VERSION ""

NS_ :

BS_:

BU_: VoltTemp_7 VoltTemp_6 VoltTemp_5 VoltTemp_4 VoltTemp_3 VoltTemp_2 VoltTemp_1 VoltTemp_0 BPS Amperes TPEE_MPPT_C TPEE_MPPT_B TPEE_MPPT_A Telemetry Pump Pedals PDU LV_Carrier External Dashboard_Display ChargerInterface Controls VCU Elcon Lighting_Rear Lighting_Right Lighting_Left Lighting_Front Lighting_Canopy Prohelion_WaveSculptor22 Bosch_LWS Vector__XXX

VAL_TABLE_ BPS_Amperes_Fault 0 "OK" 1 "Out-of-Bounds" 2 "Over-Current (Discharge)" 3 "Over-Current (Charge)" 4 "Message Watchdog" ;
VAL_TABLE_ BPS_Volt_Tap_Fault 0 "OK" 1 "BQ I2C Read Error" 2 "Out-of-Bounds" 3 "Over-Voltage" 4 "Under-Voltage" 5 "Message Watchdog" ;
VAL_TABLE_ BPS_Temp_Tap_Fault 0 "OK" 1 "Out-of-Bounds (Short to GND)" 2 "Out-of-Bounds (Short to VCC)" 3 "Disconnected" 4 "Over-Temperature" 5 "Charge Over-Temperature" 6 "Under-Temperature" 7 "Charge Under-Temperature" 8 "Message Watchdog" ;
VAL_TABLE_ BPS_Module_Override 0 "NORMAL_OPERATION" 1 "VOLTAGE_OVERRIDE" 2 "TEMP_OVERRIDE" 3 "OVERRIDE_ALL" ;
VAL_TABLE_ BQ25756E_Error 0 "OK" 1 "i2c_error" 2 "Input_UV" 3 "Input_OV" 4 "Battery_OC" 5 "Battery_OV" 6 "Over-Temperature" ;
VAL_TABLE_ Motor_Command_Source 0 "VCU" 1 "Tritium External" ;
VAL_TABLE_ Supplemental_Battery_Fault 0 "OK" 1 "Under-Voltage" 2 "Over-Voltage" 3 "Over-Current (Discharge)" 4 "Over-Current (Charge)" 5 "Unknown Fault" ;
VAL_TABLE_ VCU_FSM_State 0 "INIT" 1 "FORWARD_DRIVE" 2 "NEUTRAL_DRIVE" 3 "REVERSE_DRIVE" 4 "REGEN" 5 "CRUISE_CONTROL" 6 "DISABLED" 7 "VEHICLE_NOT_READY" ;
VAL_TABLE_ Generic_TrueFalse 0 "False" 1 "True" ;
VAL_TABLE_ Fusebox_Assignments 0 "VCU" 1 "Dashboard" 2 "Horn" 3 "Lights" 4 "Pi + Display" 5 "Pedals" 6 "Cameras" 7 "Unassigned_0" 8 "Battery" 9 "MPPTs" 10 "Motor Controller" 11 "Telemetry + Data Acq" 12 "Pump" 13 "Unassigned_1" 14 "Unassigned_2" 15 "PDE Fans" ;
VAL_TABLE_ Generic_Active 0 "Inactive" 1 "Active" ;
VAL_TABLE_ SuppCharger_Status 0 "Charge Disabled" 1 "Trickle Charging" 2 "Precharge" 3 "Fast Charging" 4 "Taper" 5 "ERROR" 6 "Topping Off" 7 "Done" ;
VAL_TABLE_ ContactorState 0 "Open" 1 "Closed" ;
VAL_TABLE_ Lighting_Board_Fault 0 "OK" 1 "Addr LED Undercurrent" 2 "LED0 Undercurrent" 3 "LED1 Undercurrent" 4 "Addr LED Overcurrent" 5 "LED0 Overcurrent" 6 "LED1 Overcurrent" 7 "Light Command Watchdog" 8 "Watchdog" ;
VAL_TABLE_ MPPT_ControlMode 0 "Disabled" 1 "Enabled" 2 "Enabled - Constant Voltage" ;
VAL_TABLE_ Generic_OnOff 0 "Off" 1 "On" ;
VAL_TABLE_ Button_Pressed 0 "-" 1 "Pressed" ;
VAL_TABLE_ Switch_Selected 0 "-" 1 "Selected" ;
VAL_TABLE_ Generic_Enable 0 "Disabled" 1 "Enabled" ;
VAL_TABLE_ Generic_OK 0 "NOT OK" 1 "OK" ;
VAL_TABLE_ Generic_Fault 0 "OK" 1 "FAULT" ;
VAL_TABLE_ MPPT_Fault 0 "OK" 1 "Configuration Error" 2 "Input Over Voltage" 3 "Output Over Voltage" 4 "Output Over Current" 5 "Input Over Current" 6 "Input Under Current" 7 "Phase Over Current" 8 "Unknown Fault" ;
VAL_TABLE_ MPPT_Mode 0 "Constant Input Voltage" 1 "Constant Input Current" 2 "Minimum Input Current" 3 "Constant Output Voltage" 4 "Constant Output Current" 5 "Temperature De-Rating" 6 "FAULT" ;
VAL_TABLE_ BPS_Fault 0 "OK" 1 "Overvoltage" 2 "Undervoltage" 3 "Regen" 4 "Overtemperature" 5 "Elcon" 6 "Array Precharge Timeout" 7 "Internal Watchdog" 8 "Segment Watchdog" 9 "HV Plus Contactor Sense" 10 "HV Minus Contactor Sense" 11 "Array Contactor Sense" 12 "Array Pchg Contactor Sense" 13 "Estop 1" 14 "Estop 2" 15 "Estop 3" 16 "Charging Overcurrent" 17 "Discharging Overcurrent" 18 "Amperes Watchdog" ;
VAL_TABLE_ Controls_Leader_Fault 0 "OK" 1 "Bosch LWS Watchdog" 2 "BPS Watchdog" 3 "Invalid Driver Inputs" 4 "Lighting Board Fault" 5 "Lighting Board Watchdog" ;
VAL_TABLE_ HSS_SetState 0 "Do Nothing" 1 "Toggle On" 2 "Toggle Off" ;
VAL_TABLE_ Elcon_MuxPage 1 "Page 1" 2 "Page 2" 3 "Page 3" 4 "Page 4" 5 "Page 5" ;
VAL_TABLE_ Lighting_CustomModes 0 "Off" 1 "Mode 1 Active" 2 "Mode 2 Active" 3 "Mode 3 Active" ;
VAL_TABLE_ Generic_Limit 0 "OK" 1 "LIMIT" ;
VAL_TABLE_ LWS_Config 3 "Sets the signal LWS_Angle to 0°" 5 "Resets calibration status" ;
VAL_TABLE_ LWS_TrimmingStatus 0 "FAULT - Sensor Not Trimmed" 1 "Sensor Trimmed" ;
VAL_TABLE_ LWS_Fault 0 "OK" 1 "Internal Fault" ;
VAL_TABLE_ LWS_CalibrationStatus 0 "Sensor Not Calibrated" 1 "Sensor Calibrated" ;

BO_ 2 BPS_VT0_Voltage_Arr: 4 VoltTemp_0
 SG_ BPS_Tap_idx : 0|5@1+ (1,0) [0|31] "" Vector__XXX
 SG_ BPS_Voltage_Tap_Data : 8|16@1+ (0.001,0) [0|65.535] "V" Vector__XXX
 SG_ BPS_Voltage_Tap_Fault : 24|8@1+ (1,0) [0|0] "" Vector__XXX

BO_ 3 BPS_VT1_Voltage_Arr: 4 VoltTemp_1
 SG_ BPS_Tap_idx : 0|5@1+ (1,0) [0|31] "" Vector__XXX
 SG_ BPS_Voltage_Tap_Data : 8|16@1+ (0.001,0) [0|65.535] "V" Vector__XXX
 SG_ BPS_Voltage_Tap_Fault : 24|8@1+ (1,0) [0|0] "" Vector__XXX

BO_ 4 BPS_VT2_Voltage_Arr: 4 VoltTemp_2
 SG_ BPS_Tap_idx : 0|5@1+ (1,0) [0|31] "" Vector__XXX
 SG_ BPS_Voltage_Tap_Data : 8|16@1+ (0.001,0) [0|65.535] "V" Vector__XXX
 SG_ BPS_Voltage_Tap_Fault : 24|8@1+ (1,0) [0|0] "" Vector__XXX

BO_ 5 BPS_VT3_Voltage_Arr: 4 VoltTemp_3
 SG_ BPS_Tap_idx : 0|5@1+ (1,0) [0|31] "" Vector__XXX
 SG_ BPS_Voltage_Tap_Data : 8|16@1+ (0.001,0) [0|65.535] "V" Vector__XXX
 SG_ BPS_Voltage_Tap_Fault : 24|8@1+ (1,0) [0|0] "" Vector__XXX

BO_ 6 BPS_VT4_Voltage_Arr: 4 VoltTemp_4
 SG_ BPS_Tap_idx : 0|5@1+ (1,0) [0|31] "" Vector__XXX
 SG_ BPS_Voltage_Tap_Data : 8|16@1+ (0.001,0) [0|65.535] "V" Vector__XXX
 SG_ BPS_Voltage_Tap_Fault : 24|8@1+ (1,0) [0|0] "" Vector__XXX

BO_ 7 BPS_VT5_Voltage_Arr: 4 VoltTemp_5
 SG_ BPS_Tap_idx : 0|5@1+ (1,0) [0|31] "" Vector__XXX
 SG_ BPS_Voltage_Tap_Data : 8|16@1+ (0.001,0) [0|65.535] "V" Vector__XXX
 SG_ BPS_Voltage_Tap_Fault : 24|8@1+ (1,0) [0|0] "" Vector__XXX

BO_ 8 BPS_VT6_Voltage_Arr: 4 VoltTemp_6
 SG_ BPS_Tap_idx : 0|5@1+ (1,0) [0|31] "" Vector__XXX
 SG_ BPS_Voltage_Tap_Data : 8|16@1+ (0.001,0) [0|65.535] "V" Vector__XXX
 SG_ BPS_Voltage_Tap_Fault : 24|8@1+ (1,0) [0|0] "" Vector__XXX

BO_ 9 BPS_VT7_Voltage_Arr: 4 VoltTemp_7
 SG_ BPS_Tap_idx : 0|5@1+ (1,0) [0|31] "" Vector__XXX
 SG_ BPS_Voltage_Tap_Data : 8|16@1+ (0.001,0) [0|65.535] "V" Vector__XXX
 SG_ BPS_Voltage_Tap_Fault : 24|8@1+ (1,0) [0|0] "" Vector__XXX

BO_ 10 BPS_Pack_Current: 5 Amperes
 SG_ BPS_Amperes_Fault : 0|8@1+ (1,0) [0|255] "" Vector__XXX
 SG_ Main_Battery_Current : 8|24@1- (0.001,0) [-8388.608|8388.607] "A" Vector__XXX
 SG_ FrameID_Amperes : 32|8@1+ (1,0) [0|255] "" Vector__XXX

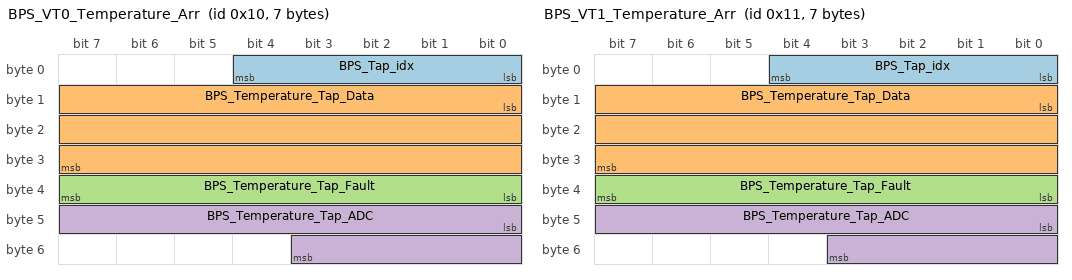
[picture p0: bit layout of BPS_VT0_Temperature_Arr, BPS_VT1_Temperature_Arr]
BO_ 16 BPS_VT0_Temperature_Arr: 7 VoltTemp_0
 SG_ BPS_Tap_idx : 0|5@1+ (1,0) [0|31] "" Vector__XXX
 SG_ BPS_Temperature_Tap_Data : 8|24@1- (0.001,0) [-8388.608|8388.607] "°C" Vector__XXX
 SG_ BPS_Temperature_Tap_Fault : 32|8@1+ (1,0) [0|255] "" Vector__XXX
 SG_ BPS_Temperature_Tap_ADC : 40|12@1+ (1,0) [0|4095] "" Vector__XXX

BO_ 17 BPS_VT1_Temperature_Arr: 7 VoltTemp_1
 SG_ BPS_Tap_idx : 0|5@1+ (1,0) [0|31] "" Vector__XXX
 SG_ BPS_Temperature_Tap_Data : 8|24@1- (0.001,0) [-8388.608|8388.607] "°C" Vector__XXX
 SG_ BPS_Temperature_Tap_Fault : 32|8@1+ (1,0) [0|255] "" Vector__XXX
 SG_ BPS_Temperature_Tap_ADC : 40|12@1+ (1,0) [0|4095] "" Vector__XXX

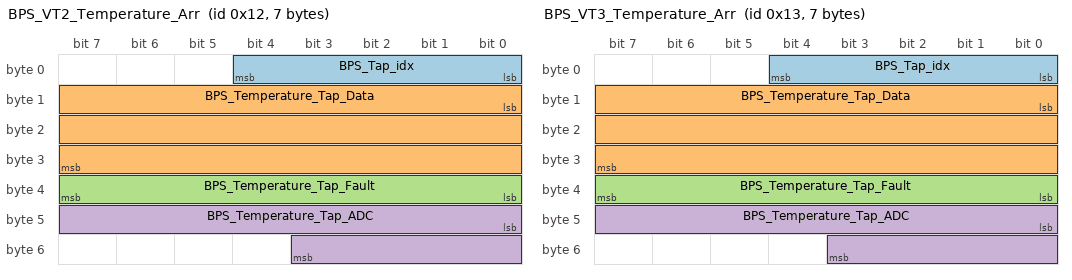
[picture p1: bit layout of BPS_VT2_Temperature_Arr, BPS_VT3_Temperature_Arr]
BO_ 18 BPS_VT2_Temperature_Arr: 7 VoltTemp_2
 SG_ BPS_Tap_idx : 0|5@1+ (1,0) [0|31] "" Vector__XXX
 SG_ BPS_Temperature_Tap_Data : 8|24@1- (0.001,0) [-8388.608|8388.607] "°C" Vector__XXX
 SG_ BPS_Temperature_Tap_Fault : 32|8@1+ (1,0) [0|255] "" Vector__XXX
 SG_ BPS_Temperature_Tap_ADC : 40|12@1+ (1,0) [0|4095] "" Vector__XXX

BO_ 19 BPS_VT3_Temperature_Arr: 7 VoltTemp_3
 SG_ BPS_Tap_idx : 0|5@1+ (1,0) [0|31] "" Vector__XXX
 SG_ BPS_Temperature_Tap_Data : 8|24@1- (0.001,0) [-8388.608|8388.607] "°C" Vector__XXX
 SG_ BPS_Temperature_Tap_Fault : 32|8@1+ (1,0) [0|255] "" Vector__XXX
 SG_ BPS_Temperature_Tap_ADC : 40|12@1+ (1,0) [0|4095] "" Vector__XXX

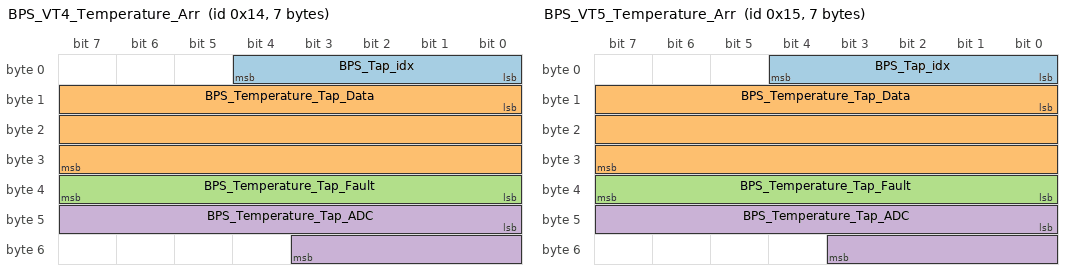
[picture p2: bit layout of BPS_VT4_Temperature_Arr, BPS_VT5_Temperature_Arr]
BO_ 20 BPS_VT4_Temperature_Arr: 7 VoltTemp_4
 SG_ BPS_Tap_idx : 0|5@1+ (1,0) [0|31] "" Vector__XXX
 SG_ BPS_Temperature_Tap_Data : 8|24@1- (0.001,0) [-8388.608|8388.607] "°C" Vector__XXX
 SG_ BPS_Temperature_Tap_Fault : 32|8@1+ (1,0) [0|255] "" Vector__XXX
 SG_ BPS_Temperature_Tap_ADC : 40|12@1+ (1,0) [0|4095] "" Vector__XXX

BO_ 21 BPS_VT5_Temperature_Arr: 7 VoltTemp_5
 SG_ BPS_Tap_idx : 0|5@1+ (1,0) [0|31] "" Vector__XXX
 SG_ BPS_Temperature_Tap_Data : 8|24@1- (0.001,0) [-8388.608|8388.607] "°C" Vector__XXX
 SG_ BPS_Temperature_Tap_Fault : 32|8@1+ (1,0) [0|255] "" Vector__XXX
 SG_ BPS_Temperature_Tap_ADC : 40|12@1+ (1,0) [0|4095] "" Vector__XXX

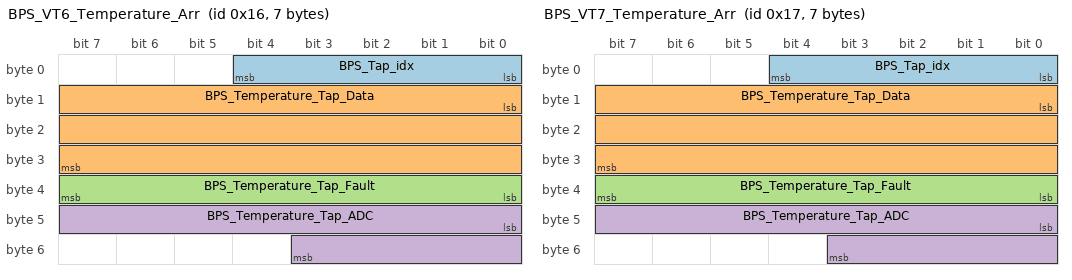
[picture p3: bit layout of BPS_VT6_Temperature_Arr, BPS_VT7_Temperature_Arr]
BO_ 22 BPS_VT6_Temperature_Arr: 7 VoltTemp_6
 SG_ BPS_Tap_idx : 0|5@1+ (1,0) [0|31] "" Vector__XXX
 SG_ BPS_Temperature_Tap_Data : 8|24@1- (0.001,0) [-8388.608|8388.607] "°C" Vector__XXX
 SG_ BPS_Temperature_Tap_Fault : 32|8@1+ (1,0) [0|255] "" Vector__XXX
 SG_ BPS_Temperature_Tap_ADC : 40|12@1+ (1,0) [0|4095] "" Vector__XXX

BO_ 23 BPS_VT7_Temperature_Arr: 7 VoltTemp_7
 SG_ BPS_Tap_idx : 0|5@1+ (1,0) [0|31] "" Vector__XXX
 SG_ BPS_Temperature_Tap_Data : 8|24@1- (0.001,0) [-8388.608|8388.607] "°C" Vector__XXX
 SG_ BPS_Temperature_Tap_Fault : 32|8@1+ (1,0) [0|255] "" Vector__XXX
 SG_ BPS_Temperature_Tap_ADC : 40|12@1+ (1,0) [0|4095] "" Vector__XXX

BO_ 1877 BPS_Pack_Current_ADC: 3 Amperes
 SG_ Main_Battery_Current_ADC : 0|12@1+ (1,0) [0|4095] "" Vector__XXX
 SG_ FrameID_Amperes : 16|8@1+ (1,0) [0|255] "" Vector__XXX

BO_ 1952 BPS_Balance_Discharge: 1 BPS
 SG_ BPS_Segment_idx : 0|3@1+ (1,0) [0|7] "" Vector__XXX
 SG_ BPS_Tap_idx : 3|5@1+ (1,0) [0|31] "" Vector__XXX

BO_ 1 BPS_Status: 8 BPS
 SG_ BPS_Fault : 0|8@1+ (1,0) [0|0] "" Vector__XXX
 SG_ BPS_Charge_OK : 8|1@1+ (1,0) [0|0] "" Vector__XXX
 SG_ BPS_Regen_OK : 9|1@1+ (1,0) [0|0] "" Vector__XXX
 SG_ HV_Plus_Contactor_State : 10|1@1+ (1,0) [0|0] "" Vector__XXX
 SG_ HV_Minus_Contactor_State : 11|1@1+ (1,0) [0|0] "" Vector__XXX
 SG_ Array_Contactor_State : 12|1@1+ (1,0) [0|0] "" Vector__XXX
 SG_ Array_Precharge_Contactor_State : 13|1@1+ (1,0) [0|0] "" Vector__XXX
 SG_ Main_Battery_Voltage : 16|24@1+ (0.001,0) [0|16777.215] "V" Vector__XXX
 SG_ Main_Battery_Avg_Temperature : 40|16@1- (0.01,0) [-327.68|327.67] "°C" Vector__XXX
 SG_ BPS_Segment0_Status : 56|1@1+ (1,0) [0|0] "" Vector__XXX
 SG_ BPS_Segment1_Status : 57|1@1+ (1,0) [0|0] "" Vector__XXX
 SG_ BPS_Segment2_Status : 58|1@1+ (1,0) [0|0] "" Vector__XXX
 SG_ BPS_Segment3_Status : 59|1@1+ (1,0) [0|0] "" Vector__XXX
 SG_ BPS_Segment4_Status : 60|1@1+ (1,0) [0|0] "" Vector__XXX
 SG_ BPS_Segment5_Status : 61|1@1+ (1,0) [0|0] "" Vector__XXX
 SG_ BPS_Segment6_Status : 62|1@1+ (1,0) [0|0] "" Vector__XXX
 SG_ BPS_Segment7_Status : 63|1@1+ (1,0) [0|0] "" Vector__XXX

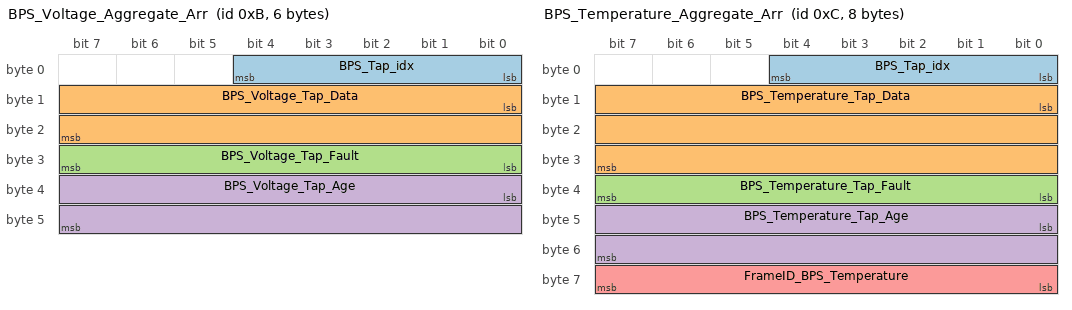
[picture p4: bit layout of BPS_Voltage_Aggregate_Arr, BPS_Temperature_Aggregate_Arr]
BO_ 11 BPS_Voltage_Aggregate_Arr: 6 BPS
 SG_ BPS_Tap_idx : 0|5@1+ (1,0) [0|31] "" Vector__XXX
 SG_ BPS_Voltage_Tap_Data : 8|16@1+ (0.001,0) [0|65.535] "V" Vector__XXX
 SG_ BPS_Voltage_Tap_Fault : 24|8@1+ (1,0) [0|0] "" Vector__XXX
 SG_ BPS_Voltage_Tap_Age : 32|16@1+ (1,0) [0|65535] "ms" Vector__XXX

BO_ 12 BPS_Temperature_Aggregate_Arr: 8 BPS
 SG_ BPS_Tap_idx : 0|5@1+ (1,0) [0|31] "" Vector__XXX
 SG_ BPS_Temperature_Tap_Data : 8|24@1- (0.001,0) [-8388.608|8388.607] "°C" Vector__XXX
 SG_ BPS_Temperature_Tap_Fault : 32|8@1+ (1,0) [0|255] "" Vector__XXX
 SG_ BPS_Temperature_Tap_Age : 40|16@1+ (1,0) [0|65535] "ms" Vector__XXX
 SG_ FrameID_BPS_Temperature : 56|8@1+ (1,0) [0|255] "" Vector__XXX

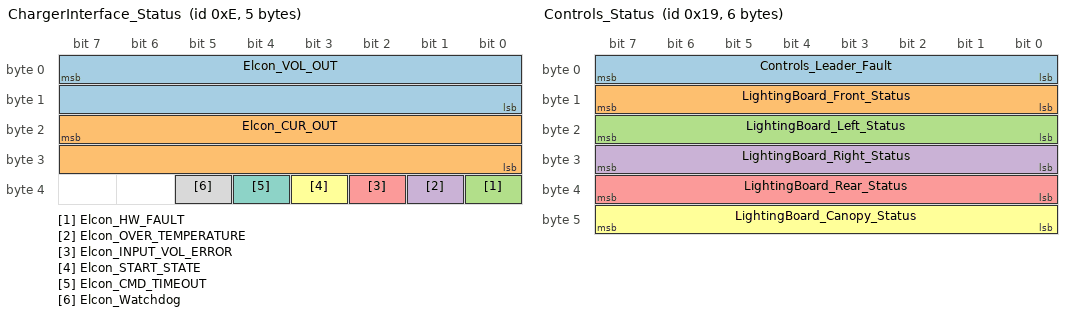
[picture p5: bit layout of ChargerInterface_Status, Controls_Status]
BO_ 14 ChargerInterface_Status: 5 ChargerInterface
 SG_ Elcon_VOL_OUT : 7|16@0+ (0.1,0) [0|6553.5] "V" Vector__XXX
 SG_ Elcon_CUR_OUT : 23|16@0+ (0.1,0) [0|6553.5] "A" Vector__XXX
 SG_ Elcon_HW_FAULT : 32|1@0+ (1,0) [0|1] "" Vector__XXX
 SG_ Elcon_OVER_TEMPERATURE : 33|1@0+ (1,0) [0|1] "" Vector__XXX
 SG_ Elcon_INPUT_VOL_ERROR : 34|1@0+ (1,0) [0|1] "" Vector__XXX
 SG_ Elcon_START_STATE : 35|1@0+ (1,0) [0|1] "" Vector__XXX
 SG_ Elcon_CMD_TIMEOUT : 36|1@0+ (1,0) [0|1] "" Vector__XXX
 SG_ Elcon_Watchdog : 37|1@0+ (1,0) [0|1] "" Vector__XXX

BO_ 15 BPS_Fault_Val_Arr: 6 BPS
 SG_ BPS_Tap_idx : 0|5@1+ (1,0) [0|31] "" Vector__XXX
 SG_ BPS_Voltage_Tap_Data : 8|16@1+ (0.001,0) [0|65.535] "V" Vector__XXX
 SG_ BPS_Temperature_Tap_Data : 24|24@1- (0.001,0) [-8388.608|8388.607] "°C" Vector__XXX

BO_ 24 VCU_Status: 6 VCU
 SG_ VCU_FSM_State : 0|4@1+ (1,0) [0|15] "" Vector__XXX
 SG_ Motor_Ready : 4|1@1+ (1,0) [0|0] "" Vector__XXX
 SG_ Motor_Precharge_Contactor_State : 5|1@1+ (1,0) [0|0] "" Vector__XXX
 SG_ Motor_Contactor_State : 6|1@1+ (1,0) [0|0] "" Vector__XXX
 SG_ VCU_Driver_Input_Watchdog : 7|1@1+ (1,0) [0|0] "" Vector__XXX
 SG_ VCU_Pedals_Watchdog : 8|1@1+ (1,0) [0|0] "" Vector__XXX
 SG_ VCU_BPS_Watchdog : 9|1@1+ (1,0) [0|0] "" Vector__XXX
 SG_ VCU_Steering_Angle_Watchdog : 10|1@1+ (1,0) [0|1] "" Vector__XXX
 SG_ VCU_BPS_FAULT_DETECTED : 11|1@1+ (1,0) [0|1] "" Vector__XXX
 SG_ VCU_CONTROLS_FAULT_DETECTED : 12|1@1+ (1,0) [0|1] "" Vector__XXX
 SG_ VCU_MTR_FAULT_DETECTED : 13|1@1+ (1,0) [0|1] "" Vector__XXX
 SG_ VCU_PEDALS_FAULT_DETECTED : 14|1@1+ (1,0) [0|1] "" Vector__XXX
 SG_ VCU_STEERING_FAULT_DETECTED : 15|1@1+ (1,0) [0|1] "" Vector__XXX
 SG_ VCU_MotorCommandSource : 16|1@1+ (1,0) [0|1] "" Vector__XXX
 SG_ VCU_Regen_Active : 17|1@1+ (1,0) [0|0] "" Vector__XXX
 SG_ VCU_Regen_OK : 18|1@1+ (1,0) [0|0] "" Vector__XXX
 SG_ VCU_MTR_PCHG_TIMEOUT : 19|1@1+ (1,0) [0|1] "" Vector__XXX
 SG_ VCU_MTR_PCHG_CONT_TIMEOUT : 20|1@1+ (1,0) [0|1] "" Vector__XXX
 SG_ VCU_MTR_PCHG_CONT_MISMATCH : 21|1@1+ (1,0) [0|1] "" Vector__XXX
 SG_ VCU_MTR_CONT_MISMATCH : 22|1@1+ (1,0) [0|1] "" Vector__XXX
 SG_ VCU_MTR_CONT_TIMEOUT : 23|1@1+ (1,0) [0|1] "" Vector__XXX
 SG_ VCU_PCHG_OV : 24|1@1+ (1,0) [0|1] "" Vector__XXX
 SG_ VCU_PCHG_UV : 25|1@1+ (1,0) [0|1] "" Vector__XXX
 SG_ VCU_MTR_OV : 26|1@1+ (1,0) [0|1] "" Vector__XXX
 SG_ VCU_MTR_UV : 27|1@1+ (1,0) [0|1] "" Vector__XXX
 SG_ VCU_OTHER_FAULT : 28|1@1+ (1,0) [0|1] "" Vector__XXX
 SG_ VCU_MTR_DIR_CHANGE_LOCKOUT : 29|1@1+ (1,0) [0|1] "" Vector__XXX
 SG_ VCU_TIPPING_WARNING : 30|1@1+ (1,0) [0|1] "" Vector__XXX
 SG_ VCU_WARN_REGEN_NOT_ALLOW : 31|1@1+ (1,0) [0|1] "" Vector__XXX
 SG_ VCU_WARN_REGEN_NOT_EN : 32|1@1+ (1,0) [0|1] "" Vector__XXX
 SG_ VCU_FSM_INP_BRAKE : 33|1@1+ (1,0) [0|1] "" Vector__XXX
 SG_ VCU_FSM_INP_PCHG_OK : 34|1@1+ (1,0) [0|1] "" Vector__XXX
 SG_ VCU_FSM_INP_CRUISE_REQ : 35|1@1+ (1,0) [0|1] "" Vector__XXX
 SG_ VCU_FSM_INP_REGEN_REQ : 36|1@1+ (1,0) [0|1] "" Vector__XXX
 SG_ VCU_FSM_INP_REGEN_ENABLE : 37|1@1+ (1,0) [0|1] "" Vector__XXX
 SG_ VCU_FSM_INP_REGEN_RDY : 38|1@1+ (1,0) [0|1] "" Vector__XXX
 SG_ VCU_FSM_INP_FORWARD : 39|1@1+ (1,0) [0|1] "" Vector__XXX
 SG_ VCU_FSM_INP_NEUTRAL : 40|1@1+ (1,0) [0|1] "" Vector__XXX
 SG_ VCU_FSM_INP_REVERSE : 41|1@1+ (1,0) [0|1] "" Vector__XXX

BO_ 25 Controls_Status: 6 Controls
 SG_ Controls_Leader_Fault : 0|8@1+ (1,0) [0|0] "" Vector__XXX
 SG_ LightingBoard_Front_Status : 8|8@1+ (1,0) [0|0] "" Vector__XXX
 SG_ LightingBoard_Left_Status : 16|8@1+ (1,0) [0|0] "" Vector__XXX
 SG_ LightingBoard_Right_Status : 24|8@1+ (1,0) [0|0] "" Vector__XXX
 SG_ LightingBoard_Rear_Status : 32|8@1+ (1,0) [0|0] "" Vector__XXX
 SG_ LightingBoard_Canopy_Status : 40|8@1+ (1,0) [0|0] "" Vector__XXX

BO_ 32 BPS_Precharge_Voltages: 6 BPS
 SG_ BPS_Precharge_Battery_Voltage : 0|24@1+ (0.001,0) [0|16777.215] "V" Vector__XXX
 SG_ BPS_Precharge_Array_Voltage : 24|24@1+ (0.001,0) [0|16777.215] "V" Vector__XXX

BO_ 33 VCU_Precharge_Voltages: 6 VCU
 SG_ VCU_Precharge_Battery_Voltage : 0|24@1+ (0.001,0) [0|16777.215] "V" Vector__XXX
 SG_ VCU_Precharge_Motor_Voltage : 24|24@1+ (0.001,0) [0|16777.215] "V" Vector__XXX

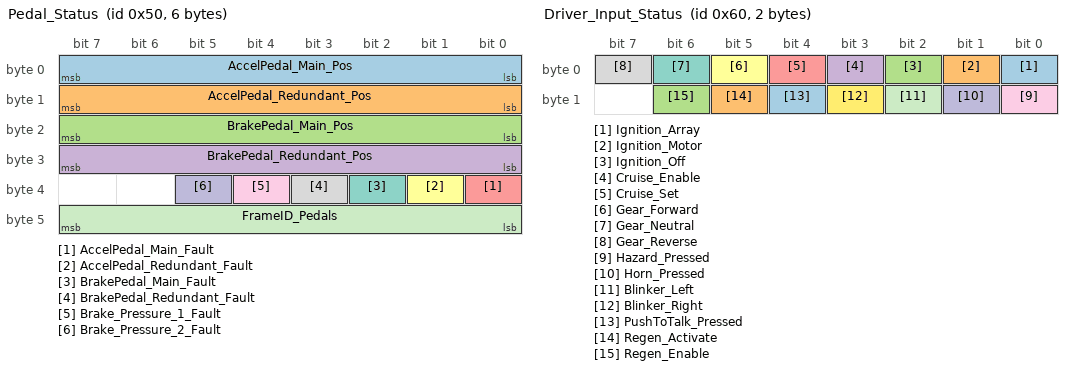
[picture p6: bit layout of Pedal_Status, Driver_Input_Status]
BO_ 80 Pedal_Status: 6 Pedals
 SG_ AccelPedal_Main_Pos : 0|8@1+ (1,0) [0|100] "%"  VCU
 SG_ AccelPedal_Redundant_Pos : 8|8@1+ (1,0) [0|100] "%"  VCU
 SG_ BrakePedal_Main_Pos : 16|8@1+ (1,0) [0|100] "%"  VCU
 SG_ BrakePedal_Redundant_Pos : 24|8@1+ (1,0) [0|100] "%"  VCU
 SG_ AccelPedal_Main_Fault : 32|1@1+ (1,0) [0|0] ""  VCU
 SG_ AccelPedal_Redundant_Fault : 33|1@1+ (1,0) [0|0] ""  VCU
 SG_ BrakePedal_Main_Fault : 34|1@1+ (1,0) [0|0] ""  VCU
 SG_ BrakePedal_Redundant_Fault : 35|1@1+ (1,0) [0|0] ""  VCU
 SG_ Brake_Pressure_1_Fault : 36|1@1+ (1,0) [0|0] "" Vector__XXX
 SG_ Brake_Pressure_2_Fault : 37|1@1+ (1,0) [0|0] "" Vector__XXX
 SG_ FrameID_Pedals : 40|8@1+ (1,0) [0|255] "" Vector__XXX

BO_ 96 Driver_Input_Status: 2 Controls
 SG_ Ignition_Array : 0|1@1+ (1,0) [0|0] ""  VCU
 SG_ Ignition_Motor : 1|1@1+ (1,0) [0|0] ""  VCU
 SG_ Ignition_Off : 2|1@1+ (1,0) [0|0] ""  VCU
 SG_ Cruise_Enable : 3|1@1+ (1,0) [0|0] ""  VCU
 SG_ Cruise_Set : 4|1@1+ (1,0) [0|0] ""  VCU
 SG_ Gear_Forward : 5|1@1+ (1,0) [0|0] ""  VCU
 SG_ Gear_Neutral : 6|1@1+ (1,0) [0|0] ""  VCU
 SG_ Gear_Reverse : 7|1@1+ (1,0) [0|0] ""  VCU
 SG_ Hazard_Pressed : 8|1@1+ (1,0) [0|0] "" Vector__XXX
 SG_ Horn_Pressed : 9|1@1+ (1,0) [0|0] "" Vector__XXX
 SG_ Blinker_Left : 10|1@1+ (1,0) [0|0] "" Vector__XXX
 SG_ Blinker_Right : 11|1@1+ (1,0) [0|0] "" Vector__XXX
 SG_ PushToTalk_Pressed : 12|1@1+ (1,0) [0|0] "" Vector__XXX
 SG_ Regen_Activate : 13|1@1+ (1,0) [0|0] ""  VCU
 SG_ Regen_Enable : 14|1@1+ (1,0) [0|0] ""  VCU

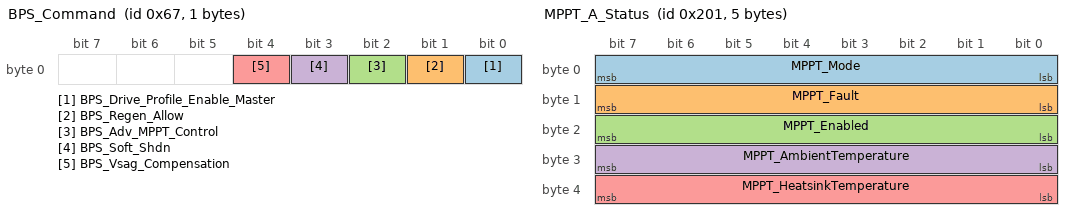
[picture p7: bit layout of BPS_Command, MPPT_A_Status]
BO_ 103 BPS_Command: 1 Controls
 SG_ BPS_Drive_Profile_Enable_Master : 0|1@1+ (1,0) [0|1] "" Vector__XXX
 SG_ BPS_Regen_Allow : 1|1@1+ (1,0) [0|1] "" Vector__XXX
 SG_ BPS_Adv_MPPT_Control : 2|1@1+ (1,0) [0|1] "" Vector__XXX
 SG_ BPS_Soft_Shdn : 3|1@1+ (1,0) [0|1] "" Vector__XXX
 SG_ BPS_Vsag_Compensation : 4|1@1+ (1,0) [0|1] "" Vector__XXX

BO_ 105 BPS_Module_Override: 8 Controls
 SG_ Module0_Override : 0|2@1+ (1,0) [0|3] "" Vector__XXX
 SG_ Module1_Override : 2|2@1+ (1,0) [0|3] "" Vector__XXX
 SG_ Module2_Override : 4|2@1+ (1,0) [0|3] "" Vector__XXX
 SG_ Module3_Override : 6|2@1+ (1,0) [0|3] "" Vector__XXX
 SG_ Module4_Override : 8|2@1+ (1,0) [0|3] "" Vector__XXX
 SG_ Module5_Override : 10|2@1+ (1,0) [0|3] "" Vector__XXX
 SG_ Module6_Override : 12|2@1+ (1,0) [0|3] "" Vector__XXX
 SG_ Module7_Override : 14|2@1+ (1,0) [0|3] "" Vector__XXX
 SG_ Module8_Override : 16|2@1+ (1,0) [0|3] "" Vector__XXX
 SG_ Module9_Override : 18|2@1+ (1,0) [0|3] "" Vector__XXX
 SG_ Module10_Override : 20|2@1+ (1,0) [0|3] "" Vector__XXX
 SG_ Module11_Override : 22|2@1+ (1,0) [0|3] "" Vector__XXX
 SG_ Module12_Override : 24|2@1+ (1,0) [0|3] "" Vector__XXX
 SG_ Module13_Override : 26|2@1+ (1,0) [0|3] "" Vector__XXX
 SG_ Module14_Override : 28|2@1+ (1,0) [0|3] "" Vector__XXX
 SG_ Module15_Override : 30|2@1+ (1,0) [0|3] "" Vector__XXX
 SG_ Module16_Override : 32|2@1+ (1,0) [0|3] "" Vector__XXX
 SG_ Module17_Override : 34|2@1+ (1,0) [0|3] "" Vector__XXX
 SG_ Module18_Override : 36|2@1+ (1,0) [0|3] "" Vector__XXX
 SG_ Module19_Override : 38|2@1+ (1,0) [0|3] "" Vector__XXX
 SG_ Module20_Override : 40|2@1+ (1,0) [0|3] "" Vector__XXX
 SG_ Module21_Override : 42|2@1+ (1,0) [0|3] "" Vector__XXX
 SG_ Module22_Override : 44|2@1+ (1,0) [0|3] "" Vector__XXX
 SG_ Module23_Override : 46|2@1+ (1,0) [0|3] "" Vector__XXX
 SG_ Module24_Override : 48|2@1+ (1,0) [0|3] "" Vector__XXX
 SG_ Module25_Override : 50|2@1+ (1,0) [0|3] "" Vector__XXX
 SG_ Module26_Override : 52|2@1+ (1,0) [0|3] "" Vector__XXX
 SG_ Module27_Override : 54|2@1+ (1,0) [0|3] "" Vector__XXX
 SG_ Module28_Override : 56|2@1+ (1,0) [0|3] "" Vector__XXX
 SG_ Module29_Override : 58|2@1+ (1,0) [0|3] "" Vector__XXX
 SG_ Module30_Override : 60|2@1+ (1,0) [0|3] "" Vector__XXX
 SG_ Module31_Override : 62|2@1+ (1,0) [0|3] "" Vector__XXX

BO_ 512 MPPT_A_PowerMeasurements: 8 TPEE_MPPT_A
 SG_ MPPT_Input_Voltage : 7|16@0- (0.01,0) [-327.68|327.67] "V" Vector__XXX
 SG_ MPPT_Input_Current : 23|16@0- (0.0005,0) [-16.384|16.3835] "A" Vector__XXX
 SG_ MPPT_Output_Voltage : 39|16@0- (0.01,0) [-327.68|327.67] "V" Vector__XXX
 SG_ MPPT_Output_Current : 55|16@0- (0.0005,0) [-16.384|16.3835] "A" Vector__XXX

BO_ 513 MPPT_A_Status: 5 TPEE_MPPT_A
 SG_ MPPT_Mode : 7|8@0+ (1,0) [0|0] "" Vector__XXX
 SG_ MPPT_Fault : 15|8@0+ (1,0) [0|0] "" Vector__XXX
 SG_ MPPT_Enabled : 23|8@0- (1,0) [0|2] "" Vector__XXX
 SG_ MPPT_AmbientTemperature : 31|8@0- (1,0) [-128|127] "°C" Vector__XXX
 SG_ MPPT_HeatsinkTemperature : 39|8@0- (1,0) [-128|127] "°C" Vector__XXX

BO_ 514 MPPT_A_SweepMeasurements: 6 TPEE_MPPT_A
 SG_ MPPT_Sweep_Data_cnt : 7|8@0+ (1,0) [0|127] "" Vector__XXX
 SG_ MPPT_Sweep_Data_Current : 23|16@0- (0.0005,0) [-16.384|16.3835] "A" Vector__XXX
 SG_ MPPT_Sweep_Data_Voltage : 39|16@0- (0.01,0) [-327.68|327.67] "V" Vector__XXX

BO_ 521 MPPT_A_SetMode: 1 BPS
 SG_ MPPT_Set_Enable : 7|8@0+ (1,0) [0|2] ""  TPEE_MPPT_A

BO_ 528 MPPT_A_PerformSweep: 5 External
 SG_ MPPT_Set_Sweep_Start : 7|16@0- (0.01,0) [-327.68|327.67] "V" Vector__XXX
 SG_ MPPT_Set_Sweep_End : 23|16@0- (0.0005,0) [-16.384|16.3835] "A" Vector__XXX
 SG_ MPPT_Set_Sweep_Size : 39|8@0+ (1,0) [4|128] "" Vector__XXX

BO_ 529 MPPT_A_SetOutputVoltageLimit: 2 BPS
 SG_ MPPT_SetOutputVoltageLimit : 7|16@0- (0.01,0) [-327.68|327.67] "V" Vector__XXX

BO_ 530 MPPT_A_SetOutputCurrentLimit: 2 BPS
 SG_ MPPT_SetOutputCurrentLimit : 7|16@0- (0.0005,0) [-16.384|16.3835] "A" Vector__XXX

BO_ 544 MPPT_B_PowerMeasurements: 8 TPEE_MPPT_B
 SG_ MPPT_Input_Voltage : 7|16@0- (0.01,0) [-327.68|327.67] "V" Vector__XXX
 SG_ MPPT_Input_Current : 23|16@0- (0.0005,0) [-16.384|16.3835] "A" Vector__XXX
 SG_ MPPT_Output_Voltage : 39|16@0- (0.01,0) [-327.68|327.67] "V" Vector__XXX
 SG_ MPPT_Output_Current : 55|16@0- (0.0005,0) [-16.384|16.3835] "A" Vector__XXX

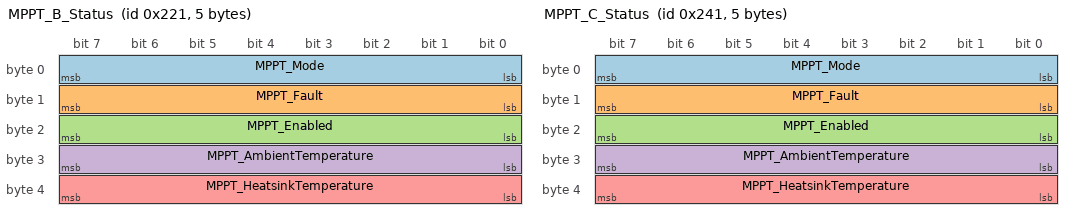
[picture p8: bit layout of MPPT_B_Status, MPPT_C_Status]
BO_ 545 MPPT_B_Status: 5 TPEE_MPPT_B
 SG_ MPPT_Mode : 7|8@0+ (1,0) [0|0] "" Vector__XXX
 SG_ MPPT_Fault : 15|8@0+ (1,0) [0|0] "" Vector__XXX
 SG_ MPPT_Enabled : 23|8@0- (1,0) [0|2] "" Vector__XXX
 SG_ MPPT_AmbientTemperature : 31|8@0- (1,0) [-128|127] "°C" Vector__XXX
 SG_ MPPT_HeatsinkTemperature : 39|8@0- (1,0) [-128|127] "°C" Vector__XXX

BO_ 546 MPPT_B_SweepMeasurements: 6 TPEE_MPPT_B
 SG_ MPPT_Sweep_Data_cnt : 7|8@0+ (1,0) [0|127] "" Vector__XXX
 SG_ MPPT_Sweep_Data_Current : 23|16@0- (0.0005,0) [-16.384|16.3835] "A" Vector__XXX
 SG_ MPPT_Sweep_Data_Voltage : 39|16@0- (0.01,0) [-327.68|327.67] "V" Vector__XXX

BO_ 553 MPPT_B_SetMode: 1 BPS
 SG_ MPPT_Set_Enable : 7|8@0+ (1,0) [0|2] "" Vector__XXX

BO_ 560 MPPT_B_PerformSweep: 5 External
 SG_ MPPT_Set_Sweep_Start : 7|16@0- (0.01,0) [-327.68|327.67] "V" Vector__XXX
 SG_ MPPT_Set_Sweep_End : 23|16@0- (0.0005,0) [-16.384|16.3835] "A" Vector__XXX
 SG_ MPPT_Set_Sweep_Size : 39|8@0+ (1,0) [4|128] "" Vector__XXX

BO_ 561 MPPT_B_SetOutputVoltageLimit: 2 BPS
 SG_ MPPT_SetOutputVoltageLimit : 7|16@0- (0.01,0) [-327.68|327.67] "V" Vector__XXX

BO_ 562 MPPT_B_SetOutputCurrentLimit: 2 BPS
 SG_ MPPT_SetOutputCurrentLimit : 7|16@0- (0.0005,0) [-16.384|16.3835] "A" Vector__XXX

BO_ 576 MPPT_C_PowerMeasurements: 8 TPEE_MPPT_C
 SG_ MPPT_Input_Voltage : 7|16@0- (0.01,0) [-327.68|327.67] "V" Vector__XXX
 SG_ MPPT_Input_Current : 23|16@0- (0.0005,0) [-16.384|16.3835] "A" Vector__XXX
 SG_ MPPT_Output_Voltage : 39|16@0- (0.01,0) [-327.68|327.67] "V" Vector__XXX
 SG_ MPPT_Output_Current : 55|16@0- (0.0005,0) [-16.384|16.3835] "A" Vector__XXX

BO_ 577 MPPT_C_Status: 5 TPEE_MPPT_C
 SG_ MPPT_Mode : 7|8@0+ (1,0) [0|0] "" Vector__XXX
 SG_ MPPT_Fault : 15|8@0+ (1,0) [0|0] "" Vector__XXX
 SG_ MPPT_Enabled : 23|8@0- (1,0) [0|2] "" Vector__XXX
 SG_ MPPT_AmbientTemperature : 31|8@0- (1,0) [-128|127] "°C" Vector__XXX
 SG_ MPPT_HeatsinkTemperature : 39|8@0- (1,0) [-128|127] "°C" Vector__XXX

BO_ 578 MPPT_C_SweepMeasurements: 6 TPEE_MPPT_C
 SG_ MPPT_Sweep_Data_cnt : 7|8@0+ (1,0) [0|127] "" Vector__XXX
 SG_ MPPT_Sweep_Data_Current : 23|16@0- (0.0005,0) [-16.384|16.3835] "A" Vector__XXX
 SG_ MPPT_Sweep_Data_Voltage : 39|16@0- (0.01,0) [-327.68|327.67] "V" Vector__XXX

BO_ 585 MPPT_C_SetMode: 1 BPS
 SG_ MPPT_Set_Enable : 7|8@0+ (1,0) [0|2] "" Vector__XXX

BO_ 592 MPPT_C_PerformSweep: 5 External
 SG_ MPPT_Set_Sweep_Start : 7|16@0- (0.01,0) [-327.68|327.67] "V" Vector__XXX
 SG_ MPPT_Set_Sweep_End : 23|16@0- (0.0005,0) [-16.384|16.3835] "A" Vector__XXX
 SG_ MPPT_Set_Sweep_Size : 39|8@0+ (1,0) [4|128] "" Vector__XXX

BO_ 593 MPPT_C_SetOutputVoltageLimit: 2 BPS
 SG_ MPPT_SetOutputVoltageLimit : 7|16@0- (0.01,0) [-327.68|327.67] "V" Vector__XXX

BO_ 594 MPPT_C_SetOutputCurrentLimit: 2 BPS
 SG_ MPPT_SetOutputCurrentLimit : 7|16@0- (0.0005,0) [-16.384|16.3835] "A" Vector__XXX

BO_ 768 Supp_Battery_Status: 6 LV_Carrier
 SG_ Supplemental_Battery_Fault : 0|8@1+ (1,0) [0|255] "" Vector__XXX
 SG_ Supplemental_Battery_Voltage : 8|16@1+ (0.001,0) [0|30] "V" Vector__XXX
 SG_ Supplemental_Battery_Current : 24|16@1- (0.001,0) [-32.768|32.767] "A" Vector__XXX
 SG_ FrameID_Supp : 40|8@1+ (1,0) [0|255] "" Vector__XXX

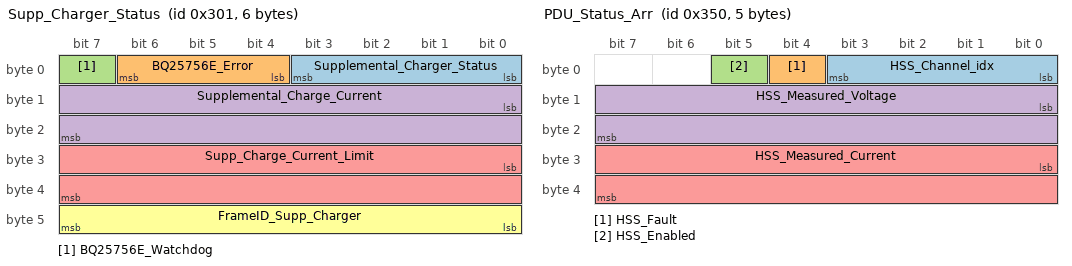
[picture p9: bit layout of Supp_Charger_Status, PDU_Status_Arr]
BO_ 769 Supp_Charger_Status: 6 LV_Carrier
 SG_ Supplemental_Charger_Status : 0|4@1+ (1,0) [0|15] "" Vector__XXX
 SG_ BQ25756E_Error : 4|3@1+ (1,0) [0|7] "" Vector__XXX
 SG_ BQ25756E_Watchdog : 7|1@1+ (1,0) [0|1] "" Vector__XXX
 SG_ Supplemental_Charge_Current : 8|16@1- (0.001,0) [-32.768|32.767] "A" Vector__XXX
 SG_ Supp_Charge_Current_Limit : 24|16@1+ (1,0) [0|65535] "mA" Vector__XXX
 SG_ FrameID_Supp_Charger : 40|8@1+ (1,0) [0|255] "" Vector__XXX

BO_ 770 Supp_Vicor_Stats: 5 LV_Carrier
 SG_ Supplemental_Vicor_Voltage : 0|16@1+ (0.001,0) [0|65.535] "V" Vector__XXX
 SG_ Supplemental_Vicor_Current : 16|16@1- (0.001,0) [-32.768|32.767] "A" Vector__XXX
 SG_ FrameID_Supp_Charger : 32|8@1+ (1,0) [0|255] "" Vector__XXX

BO_ 848 PDU_Status_Arr: 5 PDU
 SG_ HSS_Channel_idx : 0|4@1+ (1,0) [0|16] "" Vector__XXX
 SG_ HSS_Fault : 4|1@1+ (1,0) [0|0] "" Vector__XXX
 SG_ HSS_Enabled : 5|1@1+ (1,0) [0|0] "" Vector__XXX
 SG_ HSS_Measured_Voltage : 8|16@1+ (0.001,0) [0|65.535] "V" Vector__XXX
 SG_ HSS_Measured_Current : 24|16@1+ (0.001,0) [0|65.535] "A" Vector__XXX

BO_ 849 PDU_Set_Switch_Arr: 1 VCU
 SG_ HSS_Channel_idx : 0|4@1+ (1,0) [0|16] "" Vector__XXX
 SG_ HSS_SetSwitch : 4|2@1+ (1,0) [0|0] ""  PDU

BO_ 850 PDU_Set_Current_Limit_Arr: 3 VCU
 SG_ HSS_Channel_idx : 0|4@1+ (1,0) [0|16] "" Vector__XXX
 SG_ HSS_Current_Limit : 8|16@1+ (0.001,0) [0|8] "A"  PDU

BO_ 1280 Pump_Status: 6 Pump
 SG_ Pump_DutyCycle : 0|8@1+ (1,0) [0|100] "" Vector__XXX
 SG_ Pump_Fault : 8|1@1+ (1,0) [0|0] "" Vector__XXX
 SG_ FlowRate_1 : 16|16@1+ (0.001,0) [0|65.535] "L/min" Vector__XXX
 SG_ FlowRate_2 : 32|16@1+ (0.001,0) [0|65.535] "L/min" Vector__XXX

BO_ 1281 Coolant_Temperature: 4 Pump
 SG_ Coolant_Temperature_1 : 0|16@1- (0.01,0) [-327.68|327.67] "°C" Vector__XXX
 SG_ Coolant_Temperature_2 : 16|16@1- (0.01,0) [-327.68|327.67] "°C" Vector__XXX

BO_ 1282 Radiator_FanSpeed: 8 Pump
 SG_ Radiator_Fan_Speed_Measurement_1 : 0|16@1+ (1,0) [0|65535] "rpm" Vector__XXX
 SG_ Radiator_Fan_Speed_Measurement_2 : 16|16@1+ (1,0) [0|65535] "rpm" Vector__XXX
 SG_ Radiator_Fan_Speed_Target_1 : 32|16@1+ (1,0) [0|65535] "rpm" Vector__XXX
 SG_ Radiator_Fan_Speed_Target_2 : 48|16@1+ (1,0) [0|65535] "rpm" Vector__XXX

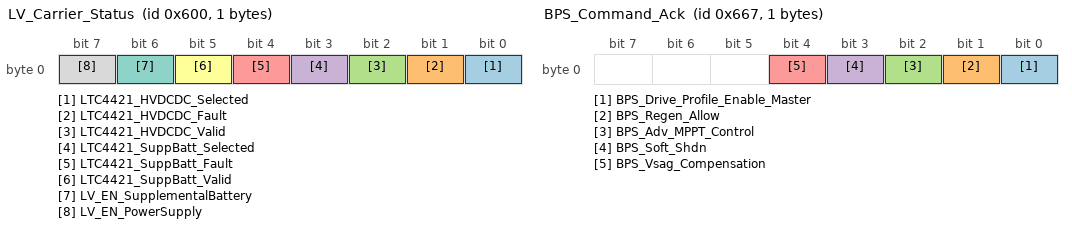
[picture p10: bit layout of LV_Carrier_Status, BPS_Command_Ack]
BO_ 1536 LV_Carrier_Status: 1 LV_Carrier
 SG_ LTC4421_HVDCDC_Selected : 0|1@1+ (1,0) [0|1] "" Vector__XXX
 SG_ LTC4421_HVDCDC_Fault : 1|1@1+ (1,0) [0|1] "" Vector__XXX
 SG_ LTC4421_HVDCDC_Valid : 2|1@1+ (1,0) [0|1] "" Vector__XXX
 SG_ LTC4421_SuppBatt_Selected : 3|1@1+ (1,0) [0|1] "" Vector__XXX
 SG_ LTC4421_SuppBatt_Fault : 4|1@1+ (1,0) [0|1] "" Vector__XXX
 SG_ LTC4421_SuppBatt_Valid : 5|1@1+ (1,0) [0|1] "" Vector__XXX
 SG_ LV_EN_SupplementalBattery : 6|1@1+ (1,0) [0|1] "" Vector__XXX
 SG_ LV_EN_PowerSupply : 7|1@1+ (1,0) [0|1] "" Vector__XXX

BO_ 1616 Brake_Pressure_1: 5 Pedals
 SG_ Brake_Pressure : 0|16@1+ (0.1,0) [0|3000] "PSI"  VCU
 SG_ Brake_Pressure_ADC : 16|12@1+ (1,0) [0|4095] ""  VCU
 SG_ FrameID_Pedals : 32|8@1+ (1,0) [0|255] "" Vector__XXX

BO_ 1617 Brake_Pressure_2: 5 Pedals
 SG_ Brake_Pressure : 0|16@1+ (0.1,0) [0|3000] "PSI" Vector__XXX
 SG_ Brake_Pressure_ADC : 16|12@1+ (1,0) [0|4095] "" Vector__XXX
 SG_ FrameID_Pedals : 32|8@1+ (1,0) [0|255] "" Vector__XXX

BO_ 1639 BPS_Command_Ack: 1 BPS
 SG_ BPS_Drive_Profile_Enable_Master : 0|1@1+ (1,0) [0|1] "" Vector__XXX
 SG_ BPS_Regen_Allow : 1|1@1+ (1,0) [0|1] "" Vector__XXX
 SG_ BPS_Adv_MPPT_Control : 2|1@1+ (1,0) [0|1] "" Vector__XXX
 SG_ BPS_Soft_Shdn : 3|1@1+ (1,0) [0|1] "" Vector__XXX
 SG_ BPS_Vsag_Compensation : 4|1@1+ (1,0) [0|1] "" Vector__XXX

BO_ 1641 BPS_Module_Override_Ack: 8 BPS
 SG_ Module0_Override : 0|2@1+ (1,0) [0|3] "" Vector__XXX
 SG_ Module1_Override : 2|2@1+ (1,0) [0|3] "" Vector__XXX
 SG_ Module2_Override : 4|2@1+ (1,0) [0|3] "" Vector__XXX
 SG_ Module3_Override : 6|2@1+ (1,0) [0|3] "" Vector__XXX
 SG_ Module4_Override : 8|2@1+ (1,0) [0|3] "" Vector__XXX
 SG_ Module5_Override : 10|2@1+ (1,0) [0|3] "" Vector__XXX
 SG_ Module6_Override : 12|2@1+ (1,0) [0|3] "" Vector__XXX
 SG_ Module7_Override : 14|2@1+ (1,0) [0|3] "" Vector__XXX
 SG_ Module8_Override : 16|2@1+ (1,0) [0|3] "" Vector__XXX
 SG_ Module9_Override : 18|2@1+ (1,0) [0|3] "" Vector__XXX
 SG_ Module10_Override : 20|2@1+ (1,0) [0|3] "" Vector__XXX
 SG_ Module11_Override : 22|2@1+ (1,0) [0|3] "" Vector__XXX
 SG_ Module12_Override : 24|2@1+ (1,0) [0|3] "" Vector__XXX
 SG_ Module13_Override : 26|2@1+ (1,0) [0|3] "" Vector__XXX
 SG_ Module14_Override : 28|2@1+ (1,0) [0|3] "" Vector__XXX
 SG_ Module15_Override : 30|2@1+ (1,0) [0|3] "" Vector__XXX
 SG_ Module16_Override : 32|2@1+ (1,0) [0|3] "" Vector__XXX
 SG_ Module17_Override : 34|2@1+ (1,0) [0|3] "" Vector__XXX
 SG_ Module18_Override : 36|2@1+ (1,0) [0|3] "" Vector__XXX
 SG_ Module19_Override : 38|2@1+ (1,0) [0|3] "" Vector__XXX
 SG_ Module20_Override : 40|2@1+ (1,0) [0|3] "" Vector__XXX
 SG_ Module21_Override : 42|2@1+ (1,0) [0|3] "" Vector__XXX
 SG_ Module22_Override : 44|2@1+ (1,0) [0|3] "" Vector__XXX
 SG_ Module23_Override : 46|2@1+ (1,0) [0|3] "" Vector__XXX
 SG_ Module24_Override : 48|2@1+ (1,0) [0|3] "" Vector__XXX
 SG_ Module25_Override : 50|2@1+ (1,0) [0|3] "" Vector__XXX
 SG_ Module26_Override : 52|2@1+ (1,0) [0|3] "" Vector__XXX
 SG_ Module27_Override : 54|2@1+ (1,0) [0|3] "" Vector__XXX
 SG_ Module28_Override : 56|2@1+ (1,0) [0|3] "" Vector__XXX
 SG_ Module29_Override : 58|2@1+ (1,0) [0|3] "" Vector__XXX
 SG_ Module30_Override : 60|2@1+ (1,0) [0|3] "" Vector__XXX
 SG_ Module31_Override : 62|2@1+ (1,0) [0|3] "" Vector__XXX

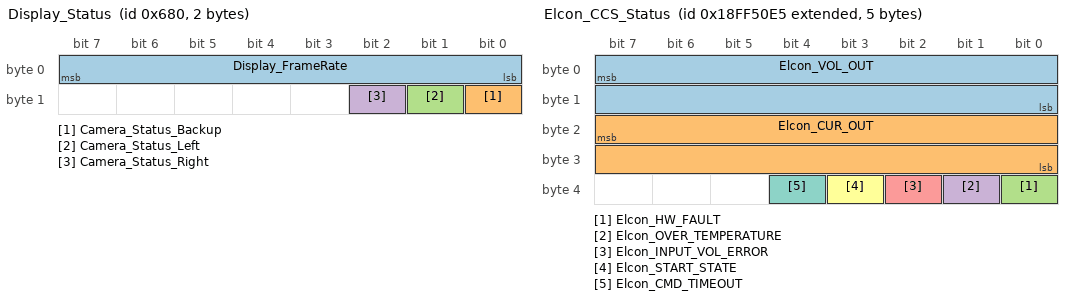
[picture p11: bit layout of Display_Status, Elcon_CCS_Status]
BO_ 1664 Display_Status: 2 Dashboard_Display
 SG_ Display_FrameRate : 0|8@1+ (1,0) [0|60] "FPS" Vector__XXX
 SG_ Camera_Status_Backup : 8|1@1+ (1,0) [0|0] "" Vector__XXX
 SG_ Camera_Status_Left : 9|1@1+ (1,0) [0|0] "" Vector__XXX
 SG_ Camera_Status_Right : 10|1@1+ (1,0) [0|0] "" Vector__XXX

BO_ 1792 Telemetry_Status: 8 Telemetry

BO_ 1872 BPS_Temp_ADC_Aggregate_Arr: 4 BPS
 SG_ BPS_Tap_idx : 0|5@1+ (1,0) [0|31] "" Vector__XXX
 SG_ BPS_Temperature_Tap_ADC : 8|12@1+ (1,0) [0|4095] "" Vector__XXX
 SG_ FrameID_BPS_Temperature : 24|8@1+ (1,0) [0|255] "" Vector__XXX

BO_ 1873 Supp_Measurements_ADC: 5 LV_Carrier
 SG_ Supp_Battery_Voltage_ADC : 0|12@1+ (1,0) [0|4095] "" Vector__XXX
 SG_ Supp_Battery_Current_ADC : 16|12@1+ (1,0) [0|4095] "" Vector__XXX
 SG_ FrameID_Supp : 32|8@1+ (1,0) [0|255] "" Vector__XXX

BO_ 1874 Supp_Vicor_Measurements_ADC: 5 LV_Carrier
 SG_ Supp_Vicor_Voltage_ADC : 0|12@1+ (1,0) [0|4095] "" Vector__XXX
 SG_ Supp_Vicor_Current_ADC : 16|12@1+ (1,0) [0|4095] "" Vector__XXX
 SG_ FrameID_Supp_Charger : 32|8@1+ (1,0) [0|255] "" Vector__XXX

BO_ 1875 Pedal_Brake_ADC: 4 Pedals
 SG_ BrakePedal_Main_ADC : 0|12@1+ (1,0) [0|4095] "" Vector__XXX
 SG_ BrakePedal_Redundant_ADC : 12|12@1+ (1,0) [0|4095] "" Vector__XXX
 SG_ FrameID_Pedals : 24|8@1+ (1,0) [0|255] "" Vector__XXX

BO_ 1876 Pedal_Accel_ADC: 4 Pedals
 SG_ AccelPedal_Main_ADC : 0|12@1+ (1,0) [0|4095] ""  VCU
 SG_ AccelPedal_Redundant_ADC : 12|12@1+ (1,0) [0|4095] ""  VCU
 SG_ FrameID_Pedals : 24|8@1+ (1,0) [0|255] "" Vector__XXX

BO_ 2550588916 Elcon_Control: 5 ChargerInterface
 SG_ Elcon_VOL_SET : 7|16@0+ (0.1,0) [0|6553.5] "V" Vector__XXX
 SG_ Elcon_CUR_SET : 23|16@0+ (0.1,0) [0|6553.5] "A" Vector__XXX
 SG_ Elcon_CONTROL_FLAG : 39|8@0+ (1,0) [0|255] "" Vector__XXX

BO_ 2550589172 Elcon_Control_Mux: 8 ChargerInterface
 SG_ Elcon_AH_NOMINAL m2 : 7|16@0+ (0.1,0) [0|6553.5] "Ah" Vector__XXX
 SG_ Elcon_BATTERY_VOL m4 : 7|16@0+ (0.1,0) [0|6553.5] "V" Vector__XXX
 SG_ Elcon_MAX_CELL_VOL m3 : 7|16@0+ (0.001,0) [0|6553.5] "V" Vector__XXX
 SG_ Elcon_NUM_CELLS_EXT m5 : 7|8@0+ (1,0) [0|255] "" Vector__XXX
 SG_ Elcon_VOL_SET m1 : 7|16@0+ (0.1,0) [0|6553.5] "V" Vector__XXX
 SG_ Elcon_AH_ACTUAL m2 : 23|16@0+ (0.1,0) [0|6553.5] "Ah" Vector__XXX
 SG_ Elcon_BATTERY_CHARGE_CUR m4 : 23|16@0+ (0.1,0) [0|6553.5] "A" Vector__XXX
 SG_ Elcon_CUR_SET m1 : 23|16@0+ (0.1,0) [0|6553.5] "A" Vector__XXX
 SG_ Elcon_MIN_CELL_VOL m3 : 23|16@0+ (0.001,0) [0|6553.5] "V" Vector__XXX
 SG_ Elcon_BATTERY_SOC m4 : 39|8@0+ (1,0) [0|100] "%" Vector__XXX
 SG_ Elcon_CELL_OV_THRESH m2 : 39|16@0+ (0.001,0) [0|6553.5] "V" Vector__XXX
 SG_ Elcon_CELL_UV_THRESH m3 : 39|16@0+ (0.001,0) [0|6553.5] "V" Vector__XXX
 SG_ Elcon_CONTROL_FLAG m1 : 39|8@0+ (1,0) [0|255] "" Vector__XXX
 SG_ Elcon_DISCUR_MAX m1 : 47|8@0+ (10,0) [0|2550] "A" Vector__XXX
 SG_ Elcon_TEMP_MAX m4 : 47|8@0+ (1,-100) [0|255] "°C" Vector__XXX
 SG_ Elcon_BATTERY_STATE_OV m3 : 48|1@0+ (1,0) [0|1] "" Vector__XXX
 SG_ Elcon_BATTERY_STATE_UV m3 : 49|1@0+ (1,0) [0|1] "" Vector__XXX
 SG_ Elcon_NUM_CELLS m2 : 55|8@0+ (1,0) [0|255] "" Vector__XXX
 SG_ Elcon_TEMP_MIN m4 : 55|8@0+ (1,-100) [0|255] "°C" Vector__XXX
 SG_ Elcon_MuxPage M : 63|8@0+ (1,0) [0|255] "" Vector__XXX

BO_ 2566869221 Elcon_CCS_Status: 5 Elcon
 SG_ Elcon_VOL_OUT : 7|16@0+ (0.1,0) [0|6553.5] "V" Vector__XXX
 SG_ Elcon_CUR_OUT : 23|16@0+ (0.1,0) [0|6553.5] "A" Vector__XXX
 SG_ Elcon_HW_FAULT : 32|1@0+ (1,0) [0|1] "" Vector__XXX
 SG_ Elcon_OVER_TEMPERATURE : 33|1@0+ (1,0) [0|1] "" Vector__XXX
 SG_ Elcon_INPUT_VOL_ERROR : 34|1@0+ (1,0) [0|1] "" Vector__XXX
 SG_ Elcon_START_STATE : 35|1@0+ (1,0) [0|1] "" Vector__XXX
 SG_ Elcon_CMD_TIMEOUT : 36|1@0+ (1,0) [0|1] "" Vector__XXX

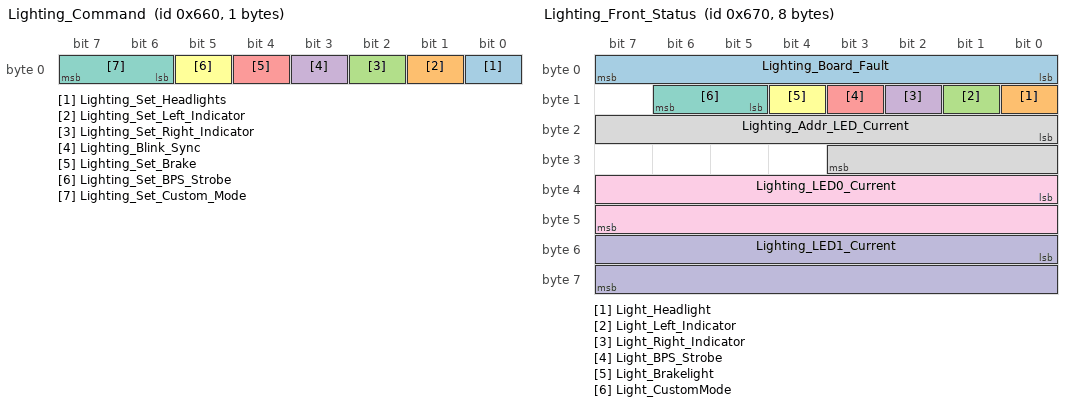
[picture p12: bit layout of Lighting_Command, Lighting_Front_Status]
BO_ 1632 Lighting_Command: 1 Controls
 SG_ Lighting_Set_Headlights : 0|1@1+ (1,0) [0|1] ""  Lighting_Right,Lighting_Left,Lighting_Canopy,Lighting_Rear,Lighting_Front
 SG_ Lighting_Set_Left_Indicator : 1|1@1+ (1,0) [0|1] ""  Lighting_Right,Lighting_Left,Lighting_Canopy,Lighting_Rear,Lighting_Front
 SG_ Lighting_Set_Right_Indicator : 2|1@1+ (1,0) [0|1] ""  Lighting_Right,Lighting_Left,Lighting_Canopy,Lighting_Rear,Lighting_Front
 SG_ Lighting_Blink_Sync : 3|1@1+ (1,0) [0|1] ""  Lighting_Right,Lighting_Left,Lighting_Canopy,Lighting_Rear,Lighting_Front
 SG_ Lighting_Set_Brake : 4|1@1+ (1,0) [0|1] ""  Lighting_Right,Lighting_Left,Lighting_Canopy,Lighting_Rear,Lighting_Front
 SG_ Lighting_Set_BPS_Strobe : 5|1@1+ (1,0) [0|1] ""  Lighting_Right,Lighting_Left,Lighting_Canopy,Lighting_Rear,Lighting_Front
 SG_ Lighting_Set_Custom_Mode : 6|2@1+ (1,0) [0|1] ""  Lighting_Right,Lighting_Left,Lighting_Canopy,Lighting_Rear,Lighting_Front

BO_ 1648 Lighting_Front_Status: 8 Lighting_Front
 SG_ Lighting_Board_Fault : 0|8@1+ (1,0) [0|255] ""  Controls
 SG_ Light_Headlight : 8|1@1+ (1,0) [0|1] ""  Controls
 SG_ Light_Left_Indicator : 9|1@1+ (1,0) [0|1] ""  Controls
 SG_ Light_Right_Indicator : 10|1@1+ (1,0) [0|1] ""  Controls
 SG_ Light_BPS_Strobe : 11|1@1+ (1,0) [0|1] ""  Controls
 SG_ Light_Brakelight : 12|1@1+ (1,0) [0|1] ""  Controls
 SG_ Light_CustomMode : 13|2@1+ (1,0) [0|1] ""  Controls
 SG_ Lighting_Addr_LED_Current : 16|12@1+ (0.001,0) [0|4.095] "A"  Controls
 SG_ Lighting_LED0_Current : 32|16@1+ (0.001,0) [0|65.535] "A"  Controls
 SG_ Lighting_LED1_Current : 48|16@1+ (0.001,0) [0|65.535] "A"  Controls

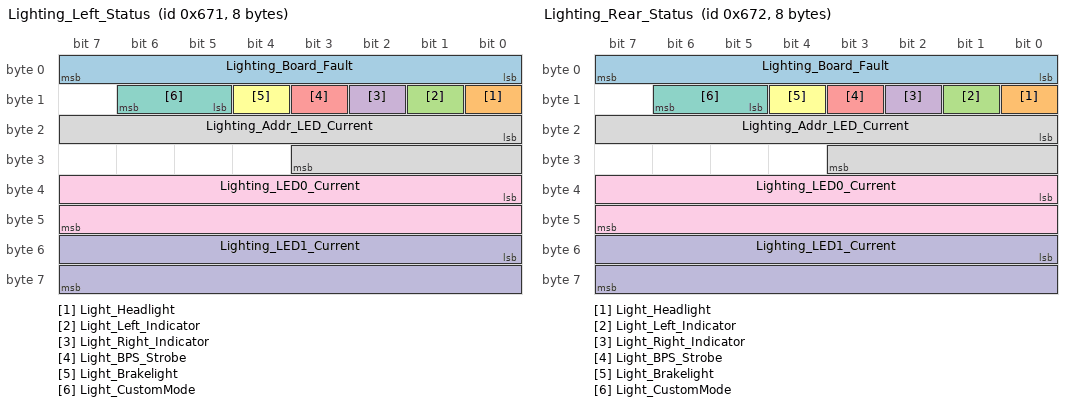
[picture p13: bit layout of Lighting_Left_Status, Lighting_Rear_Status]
BO_ 1649 Lighting_Left_Status: 8 Lighting_Left
 SG_ Lighting_Board_Fault : 0|8@1+ (1,0) [0|255] "" Vector__XXX
 SG_ Light_Headlight : 8|1@1+ (1,0) [0|1] "" Vector__XXX
 SG_ Light_Left_Indicator : 9|1@1+ (1,0) [0|1] "" Vector__XXX
 SG_ Light_Right_Indicator : 10|1@1+ (1,0) [0|1] "" Vector__XXX
 SG_ Light_BPS_Strobe : 11|1@1+ (1,0) [0|1] "" Vector__XXX
 SG_ Light_Brakelight : 12|1@1+ (1,0) [0|1] "" Vector__XXX
 SG_ Light_CustomMode : 13|2@1+ (1,0) [0|1] "" Vector__XXX
 SG_ Lighting_Addr_LED_Current : 16|12@1+ (0.001,0) [0|4.095] "A" Vector__XXX
 SG_ Lighting_LED0_Current : 32|16@1+ (0.001,0) [0|65.535] "A" Vector__XXX
 SG_ Lighting_LED1_Current : 48|16@1+ (0.001,0) [0|65.535] "A" Vector__XXX

BO_ 1650 Lighting_Rear_Status: 8 Lighting_Rear
 SG_ Lighting_Board_Fault : 0|8@1+ (1,0) [0|255] "" Vector__XXX
 SG_ Light_Headlight : 8|1@1+ (1,0) [0|1] "" Vector__XXX
 SG_ Light_Left_Indicator : 9|1@1+ (1,0) [0|1] "" Vector__XXX
 SG_ Light_Right_Indicator : 10|1@1+ (1,0) [0|1] "" Vector__XXX
 SG_ Light_BPS_Strobe : 11|1@1+ (1,0) [0|1] "" Vector__XXX
 SG_ Light_Brakelight : 12|1@1+ (1,0) [0|1] "" Vector__XXX
 SG_ Light_CustomMode : 13|2@1+ (1,0) [0|1] "" Vector__XXX
 SG_ Lighting_Addr_LED_Current : 16|12@1+ (0.001,0) [0|4.095] "A" Vector__XXX
 SG_ Lighting_LED0_Current : 32|16@1+ (0.001,0) [0|65.535] "A" Vector__XXX
 SG_ Lighting_LED1_Current : 48|16@1+ (0.001,0) [0|65.535] "A" Vector__XXX

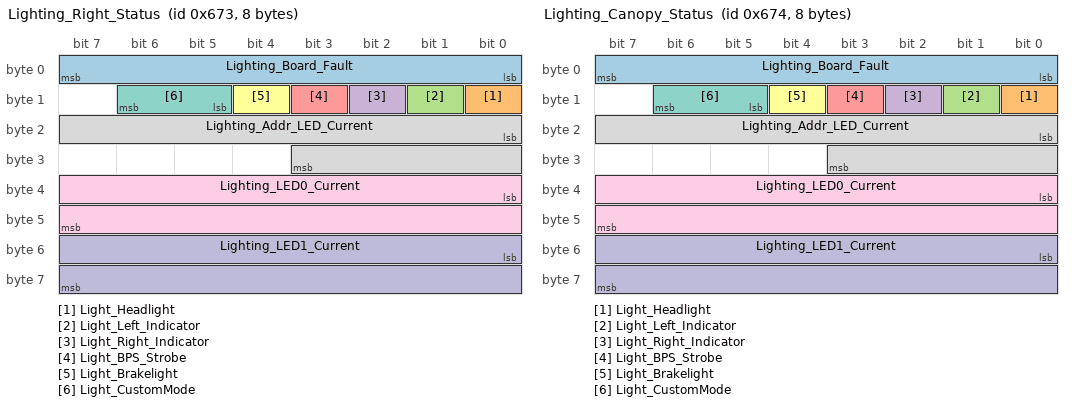
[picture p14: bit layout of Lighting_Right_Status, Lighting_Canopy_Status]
BO_ 1651 Lighting_Right_Status: 8 Lighting_Right
 SG_ Lighting_Board_Fault : 0|8@1+ (1,0) [0|255] "" Vector__XXX
 SG_ Light_Headlight : 8|1@1+ (1,0) [0|1] "" Vector__XXX
 SG_ Light_Left_Indicator : 9|1@1+ (1,0) [0|1] "" Vector__XXX
 SG_ Light_Right_Indicator : 10|1@1+ (1,0) [0|1] "" Vector__XXX
 SG_ Light_BPS_Strobe : 11|1@1+ (1,0) [0|1] "" Vector__XXX
 SG_ Light_Brakelight : 12|1@1+ (1,0) [0|1] "" Vector__XXX
 SG_ Light_CustomMode : 13|2@1+ (1,0) [0|1] "" Vector__XXX
 SG_ Lighting_Addr_LED_Current : 16|12@1+ (0.001,0) [0|4.095] "A" Vector__XXX
 SG_ Lighting_LED0_Current : 32|16@1+ (0.001,0) [0|65.535] "A" Vector__XXX
 SG_ Lighting_LED1_Current : 48|16@1+ (0.001,0) [0|65.535] "A" Vector__XXX

BO_ 1652 Lighting_Canopy_Status: 8 Lighting_Canopy
 SG_ Lighting_Board_Fault : 0|8@1+ (1,0) [0|255] "" Vector__XXX
 SG_ Light_Headlight : 8|1@1+ (1,0) [0|1] "" Vector__XXX
 SG_ Light_Left_Indicator : 9|1@1+ (1,0) [0|1] "" Vector__XXX
 SG_ Light_Right_Indicator : 10|1@1+ (1,0) [0|1] "" Vector__XXX
 SG_ Light_BPS_Strobe : 11|1@1+ (1,0) [0|1] "" Vector__XXX
 SG_ Light_Brakelight : 12|1@1+ (1,0) [0|1] "" Vector__XXX
 SG_ Light_CustomMode : 13|2@1+ (1,0) [0|1] "" Vector__XXX
 SG_ Lighting_Addr_LED_Current : 16|12@1+ (0.001,0) [0|4.095] "A" Vector__XXX
 SG_ Lighting_LED0_Current : 32|16@1+ (0.001,0) [0|65.535] "A" Vector__XXX
 SG_ Lighting_LED1_Current : 48|16@1+ (0.001,0) [0|65.535] "A" Vector__XXX

BO_ 1025 MC_DriveCommand: 8 VCU
 SG_ MC_MotorVelocitySetpoint : 0|32@1- (1,0) [0|12000] "rpm"  Prohelion_WaveSculptor22
 SG_ MC_MotorCurrentSetpoint : 32|32@1- (1,0) [0|1] "%"  Prohelion_WaveSculptor22

BO_ 1026 MC_PowerCommand: 4 VCU
 SG_ MC_MotorPowerSetpoint : 0|32@1- (1,0) [0|1] "%"  Prohelion_WaveSculptor22

BO_ 1027 MC_ResetCommand: 1 VCU
 SG_ MC_Reset : 0|8@1+ (1,0) [0|0] "" Vector__XXX

BO_ 1056 MC_Info: 8 Prohelion_WaveSculptor22
 SG_ MC_TritiumID : 0|32@1+ (1,0) [0|0] "" Vector__XXX
 SG_ MC_SerialNumber : 32|32@1+ (1,0) [0|0] "" Vector__XXX

BO_ 1057 MC_Status: 8 Prohelion_WaveSculptor22
 SG_ MC_LIMIT_OutputVoltagePWM : 0|1@1+ (1,0) [0|1] "" Vector__XXX
 SG_ MC_LIMIT_MotorCurrent : 1|1@1+ (1,0) [0|1] "" Vector__XXX
 SG_ MC_LIMIT_Velocity : 2|1@1+ (1,0) [0|1] "" Vector__XXX
 SG_ MC_LIMIT_BusCurrent : 3|1@1+ (1,0) [0|1] "" Vector__XXX
 SG_ MC_LIMIT_BusVoltageUpper : 4|1@1+ (1,0) [0|1] "" Vector__XXX
 SG_ MC_LIMIT_BusVoltageLower : 5|1@1+ (1,0) [0|1] "" Vector__XXX
 SG_ MC_LIMIT_MotorTemp : 6|1@1+ (1,0) [0|1] "" Vector__XXX
 SG_ MC_LIMIT_Reserved : 7|9@1+ (1,0) [0|511] "" Vector__XXX
 SG_ MC_FAULT_HardwareOverCurrent : 16|1@1+ (1,0) [0|1] "" Vector__XXX
 SG_ MC_FAULT_SoftwareOverCurrent : 17|1@1+ (1,0) [0|1] "" Vector__XXX
 SG_ MC_FAULT_DcBusOverVoltage : 18|1@1+ (1,0) [0|1] "" Vector__XXX
 SG_ MC_FAULT_BadMotorPositionHallSeq : 19|1@1+ (1,0) [0|1] "" Vector__XXX
 SG_ MC_FAULT_WatchdogCausedLastReset : 20|1@1+ (1,0) [0|1] "" Vector__XXX
 SG_ MC_FAULT_ConfigRead : 21|1@1+ (1,0) [0|1] "" Vector__XXX
 SG_ MC_FAULT_15vRailUnderVoltage : 22|1@1+ (1,0) [0|1] "" Vector__XXX
 SG_ MC_FAULT_DesaturationFault : 23|1@1+ (1,0) [0|1] "" Vector__XXX
 SG_ MC_FAULT_MotorOverSpeed : 24|1@1+ (1,0) [0|1] "" Vector__XXX
 SG_ MC_FAULT_Reserved : 25|7@1+ (1,0) [0|0] "" Vector__XXX
 SG_ MC_ActiveMotor : 32|16@1+ (1,0) [0|0] "" Vector__XXX
 SG_ MC_TxErrorCount : 48|8@1+ (1,0) [0|0] "" Vector__XXX
 SG_ MC_RxErrorCount : 56|8@1+ (1,0) [0|0] "" Vector__XXX

BO_ 1058 MC_BusMeasurement: 8 Prohelion_WaveSculptor22
 SG_ MC_BusVoltage : 0|32@1- (1,0) [0|0] "V" Vector__XXX
 SG_ MC_BusCurrent : 32|32@1- (1,0) [0|0] "A" Vector__XXX

BO_ 1059 MC_VelocityMeasurement: 8 Prohelion_WaveSculptor22
 SG_ MC_MotorVelocity : 0|32@1- (1,0) [0|0] "rpm" Vector__XXX
 SG_ MC_VehicleVelocity : 32|32@1- (1,0) [0|0] "m/s" Vector__XXX

BO_ 1060 MC_PhaseCurrentMeasurement: 8 Prohelion_WaveSculptor22
 SG_ MC_PhaseCurrentB : 0|32@1- (1,0) [0|0] "A_rms" Vector__XXX
 SG_ MC_PhaseCurrentC : 32|32@1- (1,0) [0|0] "A_rms" Vector__XXX

BO_ 1061 MC_MotorVoltageVectorMeasurement: 8 Prohelion_WaveSculptor22
 SG_ MC_Vq : 0|32@1- (1,0) [0|0] "V" Vector__XXX
 SG_ MC_Vd : 32|32@1- (1,0) [0|0] "V" Vector__XXX

BO_ 1062 MC_MotorCurrentVectorMeasurement: 8 Prohelion_WaveSculptor22
 SG_ MC_Iq : 0|32@1- (1,0) [0|0] "A" Vector__XXX
 SG_ MC_Id : 32|32@1- (1,0) [0|0] "A" Vector__XXX

BO_ 1063 MC_BackEMFMeasurementPrediction: 8 Prohelion_WaveSculptor22
 SG_ MC_BEMFq : 0|32@1- (1,0) [0|0] "V" Vector__XXX
 SG_ MC_BEMFd : 32|32@1- (1,0) [0|0] "V" Vector__XXX

BO_ 1064 MC_15V_RailMeasurement: 8 Prohelion_WaveSculptor22
 SG_ MC_Supply15V : 32|32@1- (1,0) [0|0] "V" Vector__XXX

BO_ 1065 MC_3V3_19V_RailMeasurement: 8 Prohelion_WaveSculptor22
 SG_ MC_Supply1V9 : 0|32@1- (1,0) [0|0] "V" Vector__XXX
 SG_ MC_Supply3V3 : 32|32@1- (1,0) [0|0] "V" Vector__XXX

BO_ 1067 MC_Motor_TempMeasurement: 8 Prohelion_WaveSculptor22
 SG_ MC_MotorTemp : 0|32@1- (1,0) [0|0] "°C" Vector__XXX
 SG_ MC_HeatsinkTemp : 32|32@1- (1,0) [0|0] "°C" Vector__XXX

BO_ 1068 MC_DspBoardTempMeasurement: 8 Prohelion_WaveSculptor22
 SG_ MC_DspBoardTemp : 0|32@1- (1,0) [0|0] "°C" Vector__XXX

BO_ 1070 MC_OdometerBusAhMeasurement: 8 Prohelion_WaveSculptor22
 SG_ MC_TripOdometer : 0|32@1- (1,0) [0|0] "m" Vector__XXX
 SG_ MC_DCBusAh : 32|32@1- (1,0) [0|0] "Ah" Vector__XXX

BO_ 1079 MC_SlipSpeedMeasurement: 8 Prohelion_WaveSculptor22
 SG_ MC_SlipSpeed : 0|32@1- (1,0) [0|0] "Hz" Vector__XXX

BO_ 1953 Set_Motor_Cmd_Src: 1 External
 SG_ Motor_Command_Source : 0|1@1+ (1,0) [0|1] "" Vector__XXX

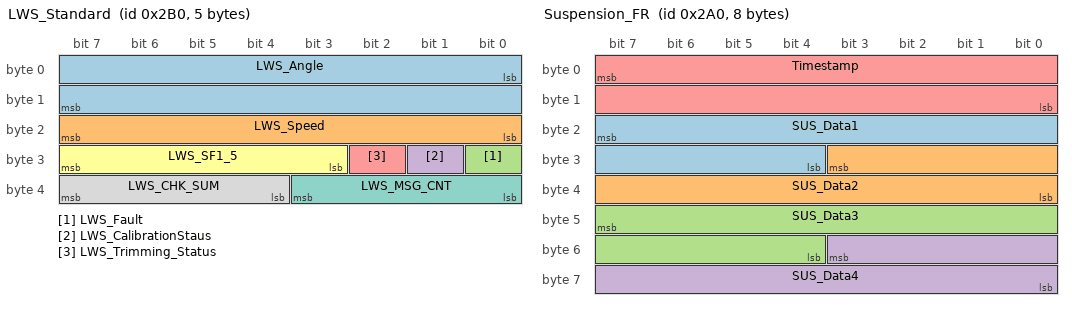
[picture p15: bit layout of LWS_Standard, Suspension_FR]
BO_ 688 LWS_Standard: 5 Bosch_LWS
 SG_ LWS_Angle : 0|16@1- (0.1,0) [-780|780] "°" Vector__XXX
 SG_ LWS_Speed : 16|8@1+ (4,0) [0|1016] "°/s" Vector__XXX
 SG_ LWS_Fault : 24|1@1+ (1,0) [0|1] "" Vector__XXX
 SG_ LWS_CalibrationStaus : 25|1@1+ (1,0) [0|1] "" Vector__XXX
 SG_ LWS_Trimming_Status : 26|1@1+ (1,0) [0|1] "" Vector__XXX
 SG_ LWS_SF1_5 : 27|5@1+ (1,0) [0|31] "" Vector__XXX
 SG_ LWS_MSG_CNT : 32|4@1+ (1,0) [0|15] "" Vector__XXX
 SG_ LWS_CHK_SUM : 36|4@1+ (1,0) [0|15] "" Vector__XXX

BO_ 1984 LWS_Config: 2 Controls
 SG_ LWS_CCW : 0|4@1+ (1,0) [0|15] "" Vector__XXX
 SG_ LWS_RES : 4|12@1+ (1,0) [0|4095] "" Vector__XXX

BO_ 192 TelemLeader_Center: 8 Vector__XXX
	SG_ Timestamp : 0|16@1+ (1,0) [0|65535] "" Vector__XXX

BO_ 416 IMU_Accel_FR: 8 Vector__XXX
	SG_ Timestamp : 7|16@0+ (1,0) [0|65535] "" Vector__XXX
	SG_ Accel_X : 23|16@0+ (1,0) [0|65535] "" Vector__XXX
	SG_ Accel_Y : 39|16@0+ (1,0) [0|65535] "" Vector__XXX
	SG_ Accel_Z : 55|16@0+ (1,0) [0|65535] "" Vector__XXX

BO_ 417 IMU_Gyro_FR: 8 Vector__XXX
	SG_ Timestamp : 7|16@0+ (1,0) [0|65535] "" Vector__XXX
	SG_ Gyro_X : 23|16@0+ (1,0) [0|65535] "" Vector__XXX
	SG_ Gyro_Y : 39|16@0+ (1,0) [0|65535] "" Vector__XXX
	SG_ Gyro_Z : 55|16@0+ (1,0) [0|65535] "" Vector__XXX

BO_ 432 IMU_Accel_Back: 8 Vector__XXX
	SG_ Timestamp : 7|16@0+ (1,0) [0|65535] "" Vector__XXX
	SG_ Accel_X : 23|16@0+ (1,0) [0|65535] "" Vector__XXX
	SG_ Accel_Y : 39|16@0+ (1,0) [0|65535] "" Vector__XXX
	SG_ Accel_Z : 55|16@0+ (1,0) [0|65535] "" Vector__XXX

BO_ 433 IMU_Gyro_Back: 8 Vector__XXX
	SG_ Timestamp : 7|16@0+ (1,0) [0|65535] "" Vector__XXX
	SG_ Gyro_X : 23|16@0+ (1,0) [0|65535] "" Vector__XXX
	SG_ Gyro_Y : 39|16@0+ (1,0) [0|65535] "" Vector__XXX
	SG_ Gyro_Z : 55|16@0+ (1,0) [0|65535] "" Vector__XXX

BO_ 464 IMU_Accel_FL: 8 Vector__XXX
	SG_ Timestamp : 7|16@0+ (1,0) [0|65535] "" Vector__XXX
	SG_ Accel_X : 23|16@0+ (1,0) [0|65535] "" Vector__XXX
	SG_ Accel_Y : 39|16@0+ (1,0) [0|65535] "" Vector__XXX
	SG_ Accel_Z : 55|16@0+ (1,0) [0|65535] "" Vector__XXX

BO_ 465 IMU_Gyro_FL: 8 Vector__XXX
	SG_ Timestamp : 7|16@0+ (1,0) [0|65535] "" Vector__XXX
	SG_ Gyro_X : 23|16@0+ (1,0) [0|65535] "" Vector__XXX
	SG_ Gyro_Y : 39|16@0+ (1,0) [0|65535] "" Vector__XXX
	SG_ Gyro_Z : 55|16@0+ (1,0) [0|65535] "" Vector__XXX

BO_ 672 Suspension_FR: 8 Vector__XXX
	SG_ SUS_Data1 : 23|12@0+ (1,0) [0|4095] "" Vector__XXX
	SG_ SUS_Data2 : 27|12@0+ (1,0) [0|4095] "" Vector__XXX
	SG_ SUS_Data3 : 47|12@0+ (1,0) [0|4095] "" Vector__XXX
	SG_ SUS_Data4 : 51|12@0+ (1,0) [0|4095] "" Vector__XXX
	SG_ Timestamp : 7|16@0+ (1,0) [0|65535] "" Vector__XXX

BO_ 720 Suspension_FL: 8 Vector__XXX
	SG_ SUS_Data1 : 23|12@0+ (1,0) [0|4095] "" Vector__XXX
	SG_ SUS_Data2 : 27|12@0+ (1,0) [0|4095] "" Vector__XXX
	SG_ SUS_Data3 : 47|12@0+ (1,0) [0|4095] "" Vector__XXX
	SG_ SUS_Data4 : 51|12@0+ (1,0) [0|4095] "" Vector__XXX
	SG_ Timestamp : 7|16@0+ (1,0) [0|65535] "" Vector__XXX

BO_ 928 Pitot_FR: 8 Vector__XXX
	SG_ Pitot_Data1 : 0|12@1+ (1,0) [0|4095] "" Vector__XXX
	SG_ Pitot_Data2 : 12|12@1+ (1,0) [0|4095] "" Vector__XXX
	SG_ Pitot_Data3 : 24|12@1+ (1,0) [0|4095] "" Vector__XXX
	SG_ Pitot_Data4 : 36|12@1+ (1,0) [0|4095] "" Vector__XXX
	SG_ Timestamp : 48|16@1+ (1,0) [0|65535] "" Vector__XXX

BO_ 976 Pitot_FL: 8 Vector__XXX
	SG_ Pitot_Data1 : 0|12@1+ (1,0) [0|4095] "" Vector__XXX
	SG_ Pitot_Data2 : 12|12@1+ (1,0) [0|4095] "" Vector__XXX
	SG_ Pitot_Data3 : 24|12@1+ (1,0) [0|4095] "" Vector__XXX
	SG_ Pitot_Data4 : 36|12@1+ (1,0) [0|4095] "" Vector__XXX
	SG_ Timestamp : 48|16@1+ (1,0) [0|65535] "" Vector__XXX

BO_ 1184 WheelRPM_FR: 8 Vector__XXX
	SG_ RPM : 0|16@1+ (1,0) [0|65535] "" Vector__XXX
	SG_ Timestamp : 16|16@1+ (1,0) [0|65535] "" Vector__XXX

BO_ 1232 WheelRPM_FL: 8 Vector__XXX
	SG_ RPM : 0|16@1+ (1,0) [0|65535] "" Vector__XXX
	SG_ Timestamp : 16|16@1+ (1,0) [0|65535] "" Vector__XXX

BO_ 1440 RideHeight_FR: 8 Vector__XXX
	SG_ RH_Data1 : 48|16@1+ (1,0) [0|65535] "" Vector__XXX
	SG_ RH_Data2 : 32|16@1+ (1,0) [0|65535] "" Vector__XXX
	SG_ RH_Data3 : 16|16@1+ (1,0) [0|65535] "" Vector__XXX
	SG_ Timestamp : 0|16@1+ (1,0) [0|65535] "" Vector__XXX

BO_ 1456 RideHeight_Back: 8 Vector__XXX
	SG_ RH_Data1 : 48|16@1+ (1,0) [0|65535] "" Vector__XXX
	SG_ RH_Data2 : 32|16@1+ (1,0) [0|65535] "" Vector__XXX
	SG_ RH_Data3 : 16|16@1+ (1,0) [0|65535] "" Vector__XXX
	SG_ Timestamp : 0|16@1+ (1,0) [0|65535] "" Vector__XXX

BO_ 1488 RideHeight_FL: 8 Vector__XXX
	SG_ RH_Data1 : 48|16@1+ (1,0) [0|65535] "" Vector__XXX
	SG_ RH_Data2 : 32|16@1+ (1,0) [0|65535] "" Vector__XXX
	SG_ RH_Data3 : 16|16@1+ (1,0) [0|65535] "" Vector__XXX
	SG_ Timestamp : 0|16@1+ (1,0) [0|65535] "" Vector__XXX

BO_ 1985 Temp_2_Center: 8 Vector__XXX
	SG_ Temperature : 0|16@1+ (1,0) [0|65535] "" Vector__XXX
	SG_ Humidity : 16|16@1+ (1,0) [0|65535] "" Vector__XXX
	SG_ Timestamp : 32|16@1+ (1,0) [0|65535] "" Vector__XXX

BO_ 2046 Sig_Wave: 8 Vector_XXX
 SG_ Sine : 0|32@1+ (1,0) [-1|1] "" Vector__XXX
 SG_ Cosine : 32|32@1+ (1,0) [-1|1] "" Vector__XXX

BO_ 4096 TelemLeader_Center: 2 Vector__XXX
 SG_ Timestamp : 0|16@1+ (1,0) [-1|65535] "" Vector__XXX

BO_ 4512 IMU_Accel_FR: 8 Vector__XXX
 SG_ Accel_X : 23|16@0- (0.000122,0) [-3.997818|3.997696] "g" Vector__XXX
 SG_ Accel_Y : 39|16@0- (0.000122,0) [-3.997818|3.997696] "g" Vector__XXX
 SG_ Accel_Z : 55|16@0- (0.000122,0) [-3.997818|3.997696] "g" Vector__XXX
 SG_ Timestamp : 7|16@0+ (1,0) [0|65535] "" Vector__XXX

BO_ 4513 IMU_Gyro_FR: 8 Vector__XXX
 SG_ Gyro_X : 23|16@0- (0.00875,0) [-286.72875|286.72] "dps" Vector__XXX
 SG_ Gyro_Y : 39|16@0- (0.00875,0) [-286.72875|286.72] "dps" Vector__XXX
 SG_ Gyro_Z : 55|16@0- (0.00875,0) [-286.72875|286.72] "dps" Vector__XXX
 SG_ Timestamp : 7|16@0+ (1,0) [0|65535] "" Vector__XXX

BO_ 4528 IMU_B_Accel: 8 Vector__XXX
 SG_ Accel_X : 23|16@0- (0.000122,0) [-3.997818|3.997696] "" Vector__XXX
 SG_ Accel_Y : 39|16@0- (0.000122,0) [-3.997818|3.997696] "" Vector__XXX
 SG_ Accel_Z : 55|16@0- (0.000122,0) [-3.997818|3.997696] "" Vector__XXX
 SG_ Timestamp : 7|16@0+ (1,0) [-1|65535] "" Vector__XXX

BO_ 4529 IMU_Gyro_Back: 8 Vector__XXX
 SG_ Gyro_X : 23|16@0- (0.00875,0) [-286.72875|286.72] "" Vector__XXX
 SG_ Gyro_Y : 39|16@0- (0.00875,0) [-286.72875|286.72] "" Vector__XXX
 SG_ Gyro_Z : 55|16@0- (0.00875,0) [-286.72875|286.72] "" Vector__XXX
 SG_ Timestamp : 7|16@0+ (1,0) [0|65535] "" Vector__XXX

BO_ 4560 IMU_Accel_FL: 8 Vector__XXX
 SG_ Accel_X : 23|16@0- (0.000122,0) [-3.997818|3.997696] "" Vector__XXX
 SG_ Accel_Y : 39|16@0- (0.000122,0) [-3.997818|3.997696] "" Vector__XXX
 SG_ Accel_Z : 55|16@0- (0.000122,0) [-3.997818|3.997696] "" Vector__XXX
 SG_ Timestamp : 7|16@0+ (1,0) [0|65535] "" Vector__XXX

BO_ 4561 IMU_Gyro_FL: 8 Vector__XXX
 SG_ Gyro_X : 23|16@0- (0.00875,0) [-286.72875|286.72] "" Vector__XXX
 SG_ Gyro_Y : 39|16@0- (0.00875,0) [-286.72875|286.72] "" Vector__XXX
 SG_ Gyro_Z : 55|16@0- (0.00875,0) [-286.72875|286.72] "" Vector__XXX
 SG_ Timestamp : 7|16@0+ (1,0) [0|65535] "" Vector__XXX

BO_ 4768 Suspension_FR: 8 Vector__XXX
 SG_ SUS_Data1 : 23|12@0+ (1,0) [0|4095] "" Vector__XXX
 SG_ SUS_Data2 : 27|12@0+ (1,0) [0|4095] "" Vector__XXX
 SG_ SUS_Data3 : 47|12@0+ (1,0) [0|4095] "" Vector__XXX
 SG_ SUS_Data4 : 51|12@0+ (1,0) [0|4095] "" Vector__XXX
 SG_ Timestamp : 7|16@0+ (1,0) [0|65535] "" Vector__XXX

BO_ 4784 Suspension_Back: 8 Vector__XXX
 SG_ SUS_Data1 : 23|12@0+ (1,0) [0|4095] "" Vector__XXX
 SG_ SUS_Data2 : 27|12@0+ (1,0) [0|4095] "" Vector__XXX
 SG_ SUS_Data3 : 47|12@0+ (1,0) [0|4095] "" Vector__XXX
 SG_ SUS_Data4 : 51|12@0+ (1,0) [0|4095] "" Vector__XXX
 SG_ Timestamp : 7|16@0+ (1,0) [0|65535] "" Vector__XXX

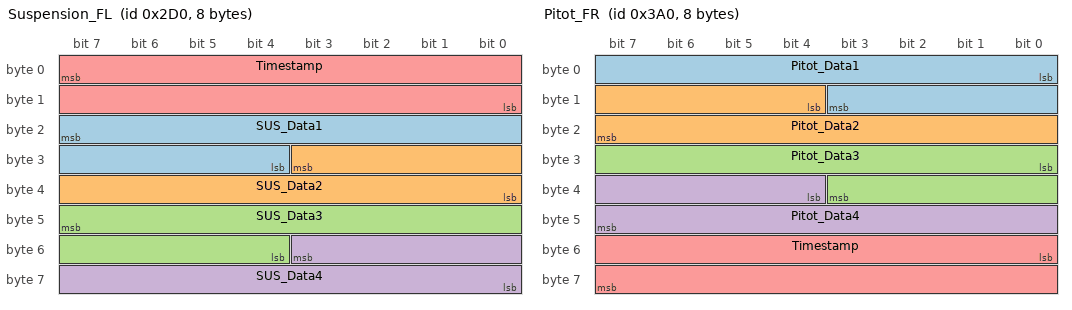
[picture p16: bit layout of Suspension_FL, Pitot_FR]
BO_ 4816 Suspension_FL: 8 Vector__XXX
 SG_ SUS_Data1 : 23|12@0+ (1,0) [0|4095] "" Vector__XXX
 SG_ SUS_Data2 : 27|12@0+ (1,0) [0|4095] "" Vector__XXX
 SG_ SUS_Data3 : 47|12@0+ (1,0) [0|4095] "" Vector__XXX
 SG_ SUS_Data4 : 51|12@0+ (1,0) [0|4095] "" Vector__XXX
 SG_ Timestamp : 7|16@0+ (1,0) [0|65535] "" Vector__XXX

BO_ 5024 Pitot_FR: 8 Vector__XXX
 SG_ Pitot_Data1 : 0|12@1+ (1,0) [0|4095] "" Vector__XXX
 SG_ Pitot_Data2 : 12|12@1+ (1,0) [0|4095] "" Vector__XXX
 SG_ Pitot_Data3 : 24|12@1+ (1,0) [0|4095] "" Vector__XXX
 SG_ Pitot_Data4 : 36|12@1+ (1,0) [0|4095] "" Vector__XXX
 SG_ Timestamp : 48|16@1+ (1,0) [0|65535] "" Vector__XXX

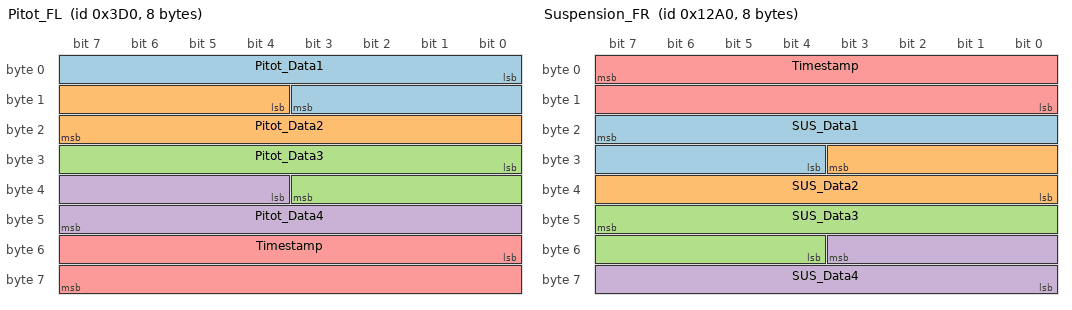
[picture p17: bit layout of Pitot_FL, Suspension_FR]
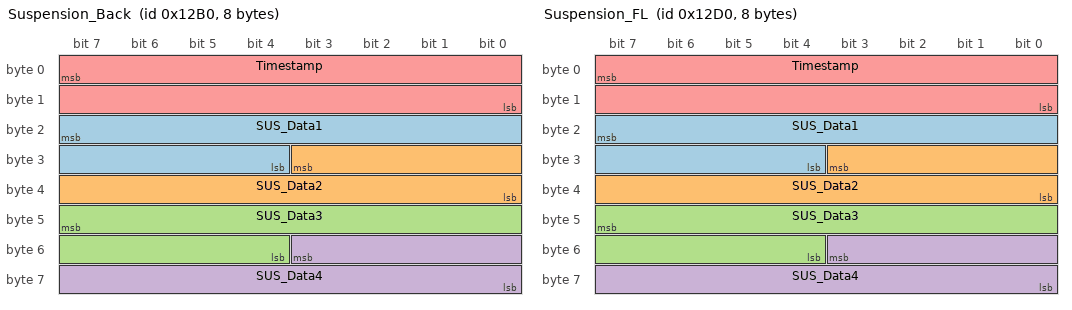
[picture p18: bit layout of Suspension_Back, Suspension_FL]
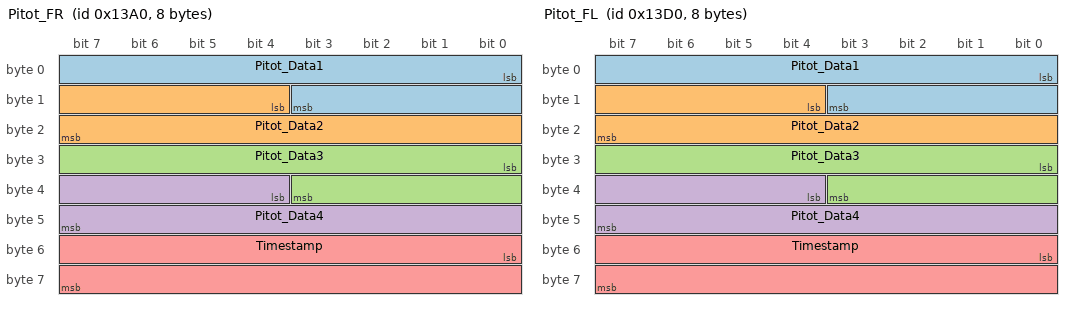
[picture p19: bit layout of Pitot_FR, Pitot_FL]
BO_ 5072 Pitot_FL: 8 Vector__XXX
 SG_ Pitot_Data1 : 0|12@1+ (1,0) [0|4095] "" Vector__XXX
 SG_ Pitot_Data2 : 12|12@1+ (1,0) [0|4095] "" Vector__XXX
 SG_ Pitot_Data3 : 24|12@1+ (1,0) [0|4095] "" Vector__XXX
 SG_ Pitot_Data4 : 36|12@1+ (1,0) [0|4095] "" Vector__XXX
 SG_ Timestamp : 48|16@1+ (1,0) [0|65535] "" Vector__XXX

BO_ 5280 WheelRPM_FR: 8 Vector__XXX
 SG_ RPM : 0|16@1+ (1,0) [0|65535] "" Vector__XXX
 SG_ Timestamp : 16|16@1+ (1,0) [0|65535] "" Vector__XXX

BO_ 5328 WheelRPM_FL: 8 Vector__XXX
 SG_ RPM : 0|16@1+ (1,0) [0|65535] "" Vector__XXX
 SG_ Timestamp : 16|16@1+ (1,0) [0|65535] "" Vector__XXX

BO_ 5536 RideHeight_FR: 8 Vector__XXX
 SG_ RH_Data1 : 48|16@1+ (1,0) [0|65535] "" Vector__XXX
 SG_ RH_Data2 : 32|16@1+ (1,0) [0|65535] "" Vector__XXX
 SG_ RH_Data3 : 16|16@1+ (1,0) [0|65535] "" Vector__XXX
 SG_ Timestamp : 0|16@1+ (1,0) [0|65535] "" Vector__XXX

BO_ 5552 RideHeight_Back: 8 Vector__XXX
 SG_ RH_Data1 : 48|16@1+ (1,0) [0|65535] "" Vector__XXX
 SG_ RH_Data2 : 32|16@1+ (1,0) [0|65535] "" Vector__XXX
 SG_ RH_Data3 : 16|16@1+ (1,0) [0|65535] "" Vector__XXX
 SG_ Timestamp : 0|16@1+ (1,0) [0|65535] "" Vector__XXX

BO_ 5584 RideHeight_FL: 8 Vector__XXX
 SG_ RH_Data1 : 48|16@1+ (1,0) [0|65535] "" Vector__XXX
 SG_ RH_Data2 : 32|16@1+ (1,0) [0|65535] "" Vector__XXX
 SG_ RH_Data3 : 16|16@1+ (1,0) [0|65535] "" Vector__XXX
 SG_ Timestamp : 0|16@1+ (1,0) [0|65535] "" Vector__XXX

BO_ 6080 Temp_1_Center: 8 Vector__XXX
 SG_ Temperature : 0|16@1+ (1,0) [0|65535] "" Vector__XXX
 SG_ Humidity : 16|16@1+ (1,0) [0|65535] "" Vector__XXX
 SG_ Timestamp : 32|16@1+ (1,0) [0|65535] "" Vector__XXX

BO_ 6081 Temp_2_Center: 6 Vector__XXX
 SG_ Temperature : 0|16@1- (1,0) [-32769|32768] "" Vector__XXX
 SG_ Humidity : 16|16@1+ (1,0) [0|65536] "" Vector__XXX
 SG_ Timestamp : 32|16@1+ (1,0) [0|65536] "" Vector__XXX

BO_ 6082 FR_IMU_Temp: 4 Vector__XXX
 SG_ Temperature : 23|16@0- (0.00703125,77) [-40|180] "" Vector__XXX
 SG_ Timestamp : 7|16@0+ (1,0) [0|65536] "" Vector__XXX

BO_ 6083 FL_IMU_Temp: 4 Vector__XXX
 SG_ Temperature : 23|16@0- (0.00703125,77) [-40|180] "" Vector__XXX
 SG_ Timestamp : 7|16@0+ (1,0) [0|65536] "" Vector__XXX

BO_ 6084 B_IMU_Temp: 4 Vector__XXX
 SG_ Temperature : 23|16@0- (0.00703125,77) [-40|180] "" Vector__XXX
 SG_ Timestamp : 7|16@0+ (1,0) [0|65536] "" Vector__XXX

BO_ 4288 GPS_Latitude: 4 Vector__XXX
 SG_ Latitude : 0|32@1- (0.000001,0) [-90|90] "°" Vector__XXX

BO_ 4289 GPS_Longitude: 4 Vector__XXX
 SG_ Longitude : 0|32@1- (0.000001,0) [-180|180] "°" Vector__XXX

CM_ BO_ 4096 "Telem Leader Node";
CM_ SG_ 2 BPS_Voltage_Tap_Data "Voltage tap measurement for the specified VoltTemp and Tap ID";
CM_ SG_ 2 BPS_Voltage_Tap_Fault "VoltTemp BQ Fault State (0 no fault, 1 fault)";
CM_ SG_ 3 BPS_Voltage_Tap_Data "Voltage tap measurement for the specified VoltTemp and Tap ID";
CM_ SG_ 3 BPS_Voltage_Tap_Fault "VoltTemp BQ Fault State (0 no fault, 1 fault)";
CM_ SG_ 4 BPS_Voltage_Tap_Data "Voltage tap measurement for the specified VoltTemp and Tap ID";
CM_ SG_ 4 BPS_Voltage_Tap_Fault "VoltTemp BQ Fault State (0 no fault, 1 fault)";
CM_ SG_ 5 BPS_Voltage_Tap_Data "Voltage tap measurement for the specified VoltTemp and Tap ID";
CM_ SG_ 5 BPS_Voltage_Tap_Fault "VoltTemp BQ Fault State (0 no fault, 1 fault)";
CM_ SG_ 6 BPS_Voltage_Tap_Data "Voltage tap measurement for the specified VoltTemp and Tap ID";
CM_ SG_ 6 BPS_Voltage_Tap_Fault "VoltTemp BQ Fault State (0 no fault, 1 fault)";
CM_ SG_ 7 BPS_Voltage_Tap_Data "Voltage tap measurement for the specified VoltTemp and Tap ID";
CM_ SG_ 7 BPS_Voltage_Tap_Fault "VoltTemp BQ Fault State (0 no fault, 1 fault)";
CM_ SG_ 8 BPS_Voltage_Tap_Data "Voltage tap measurement for the specified VoltTemp and Tap ID";
CM_ SG_ 8 BPS_Voltage_Tap_Fault "VoltTemp BQ Fault State (0 no fault, 1 fault)";
CM_ SG_ 9 BPS_Voltage_Tap_Data "Voltage tap measurement for the specified VoltTemp and Tap ID";
CM_ SG_ 9 BPS_Voltage_Tap_Fault "VoltTemp BQ Fault State (0 no fault, 1 fault)";
CM_ SG_ 10 BPS_Amperes_Fault "BPS Fault State (0 for all clear; see value table for specific faults)";
CM_ SG_ 10 Main_Battery_Current "Main battery current as measured by the BPS";
CM_ SG_ 16 BPS_Temperature_Tap_Data "Temperature tap measurement for the specified VoltTemp and Tap ID";
CM_ SG_ 16 BPS_Temperature_Tap_Fault "VoltTemp Temperature Tap Fault State (0 no fault, 1 fault)";
CM_ SG_ 16 BPS_Temperature_Tap_ADC "Raw thermistor voltage measurement for the specified VoltTemp and Tap ID";
CM_ SG_ 17 BPS_Temperature_Tap_Data "Temperature tap measurement for the specified VoltTemp and Tap ID";
CM_ SG_ 17 BPS_Temperature_Tap_Fault "VoltTemp Temperature Tap Fault State (0 no fault, 1 fault)";
CM_ SG_ 17 BPS_Temperature_Tap_ADC "Raw thermistor voltage measurement for the specified VoltTemp and Tap ID";
CM_ SG_ 18 BPS_Temperature_Tap_Data "Temperature tap measurement for the specified VoltTemp and Tap ID";
CM_ SG_ 18 BPS_Temperature_Tap_Fault "VoltTemp Temperature Tap Fault State (0 no fault, 1 fault)";
CM_ SG_ 18 BPS_Temperature_Tap_ADC "Raw thermistor voltage measurement for the specified VoltTemp and Tap ID";
CM_ SG_ 19 BPS_Temperature_Tap_Data "Temperature tap measurement for the specified VoltTemp and Tap ID";
CM_ SG_ 19 BPS_Temperature_Tap_Fault "VoltTemp Temperature Tap Fault State (0 no fault, 1 fault)";
CM_ SG_ 19 BPS_Temperature_Tap_ADC "Raw thermistor voltage measurement for the specified VoltTemp and Tap ID";
CM_ SG_ 20 BPS_Temperature_Tap_Data "Temperature tap measurement for the specified VoltTemp and Tap ID";
CM_ SG_ 20 BPS_Temperature_Tap_Fault "VoltTemp Temperature Tap Fault State (0 no fault, 1 fault)";
CM_ SG_ 20 BPS_Temperature_Tap_ADC "Raw thermistor voltage measurement for the specified VoltTemp and Tap ID";
CM_ SG_ 21 BPS_Temperature_Tap_Data "Temperature tap measurement for the specified VoltTemp and Tap ID";
CM_ SG_ 21 BPS_Temperature_Tap_Fault "VoltTemp Temperature Tap Fault State (0 no fault, 1 fault)";
CM_ SG_ 21 BPS_Temperature_Tap_ADC "Raw thermistor voltage measurement for the specified VoltTemp and Tap ID";
CM_ SG_ 22 BPS_Temperature_Tap_Data "Temperature tap measurement for the specified VoltTemp and Tap ID";
CM_ SG_ 22 BPS_Temperature_Tap_Fault "VoltTemp Temperature Tap Fault State (0 no fault, 1 fault)";
CM_ SG_ 22 BPS_Temperature_Tap_ADC "Raw thermistor voltage measurement for the specified VoltTemp and Tap ID";
CM_ SG_ 23 BPS_Temperature_Tap_Data "Temperature tap measurement for the specified VoltTemp and Tap ID";
CM_ SG_ 23 BPS_Temperature_Tap_Fault "VoltTemp Temperature Tap Fault State (0 no fault, 1 fault)";
CM_ SG_ 23 BPS_Temperature_Tap_ADC "Raw thermistor voltage measurement for the specified VoltTemp and Tap ID";
CM_ SG_ 1877 Main_Battery_Current_ADC "Main battery current raw voltage as measured by the BPS";
CM_ SG_ 1 BPS_Fault "BPS Fault State (0 for all clear; see value table for specific faults)";
CM_ SG_ 1 BPS_Charge_OK "BPS has determined charging the pack is OK (0 not ok, 1 ok)";
CM_ SG_ 1 BPS_Regen_OK "BPS has determined regenerative braking is OK (0 not ok, 1 ok)";
CM_ SG_ 1 HV_Plus_Contactor_State "HV+ Contactor State (0 open, 1 closed)";
CM_ SG_ 1 HV_Minus_Contactor_State "HV- Contactor State (0 open, 1 closed)";
CM_ SG_ 1 Array_Contactor_State "Array Main Contactor State (0 open, 1 closed)";
CM_ SG_ 1 Array_Precharge_Contactor_State "Array Precharge Contactor State (0 open, 1 closed)";
CM_ SG_ 1 Main_Battery_Voltage "Total battery pack voltage as determined by the BPS";
CM_ SG_ 1 Main_Battery_Avg_Temperature "Average pack temperature as determined by the BPS";
CM_ SG_ 11 BPS_Voltage_Tap_Data "Voltage tap measurement for the specified VoltTemp and Tap ID";
CM_ SG_ 11 BPS_Voltage_Tap_Fault "VoltTemp BQ Fault State (0 no fault, 1 fault)";
CM_ SG_ 12 BPS_Temperature_Tap_Data "Temperature tap measurement for the specified VoltTemp and Tap ID";
CM_ SG_ 12 BPS_Temperature_Tap_Fault "VoltTemp Temperature Tap Fault State (0 no fault, 1 fault)";
CM_ SG_ 15 BPS_Voltage_Tap_Data "Voltage tap measurement for the specified VoltTemp and Tap ID";
CM_ SG_ 15 BPS_Temperature_Tap_Data "Temperature tap measurement for the specified VoltTemp and Tap ID";
CM_ SG_ 24 VCU_FSM_State "VCU finite state machine current state (TODO: value table when states finalized)";
CM_ SG_ 24 Motor_Ready "VCU has determined the motor controller is ready to receive torque commands";
CM_ SG_ 24 Motor_Precharge_Contactor_State "Motor Precharge Contactor State (0 open, 1 closed)";
CM_ SG_ 24 Motor_Contactor_State "Motor Main Contactor State (0 open, 1 closed)";
CM_ SG_ 24 VCU_Driver_Input_Watchdog "VCU is receiving valid data from driver inputs (dash/steering)";
CM_ SG_ 24 VCU_Pedals_Watchdog "VCU is receiving valid data from accel/brake pedal position sensors";
CM_ SG_ 24 VCU_BPS_Watchdog "VCU is receiving valid data from driver inputs (dash/steering)";
CM_ SG_ 24 VCU_BPS_FAULT_DETECTED "VCU Fault State (0 for all clear; see value table for specific faults)";
CM_ SG_ 24 VCU_CONTROLS_FAULT_DETECTED "VCU Fault State (0 for all clear; see value table for specific faults)";
CM_ SG_ 24 VCU_MTR_FAULT_DETECTED "VCU Fault State (0 for all clear; see value table for specific faults)";
CM_ SG_ 24 VCU_PEDALS_FAULT_DETECTED "VCU Fault State (0 for all clear; see value table for specific faults)";
CM_ SG_ 24 VCU_STEERING_FAULT_DETECTED "VCU Fault State (0 for all clear; see value table for specific faults)";
CM_ SG_ 24 VCU_Regen_Active "VCU is actively applying regenerative braking";
CM_ SG_ 24 VCU_Regen_OK "VCU has determined regenerative braking can be applied";
CM_ SG_ 24 VCU_MTR_PCHG_TIMEOUT "VCU Fault State (0 for all clear; see value table for specific faults)";
CM_ SG_ 24 VCU_MTR_PCHG_CONT_TIMEOUT "VCU Fault State (0 for all clear; see value table for specific faults)";
CM_ SG_ 24 VCU_MTR_PCHG_CONT_MISMATCH "VCU Fault State (0 for all clear; see value table for specific faults)";
CM_ SG_ 24 VCU_MTR_CONT_MISMATCH "VCU Fault State (0 for all clear; see value table for specific faults)";
CM_ SG_ 24 VCU_MTR_CONT_TIMEOUT "VCU Fault State (0 for all clear; see value table for specific faults)";
CM_ SG_ 24 VCU_PCHG_OV "VCU Fault State (0 for all clear; see value table for specific faults)";
CM_ SG_ 24 VCU_PCHG_UV "VCU Fault State (0 for all clear; see value table for specific faults)";
CM_ SG_ 24 VCU_MTR_OV "VCU Fault State (0 for all clear; see value table for specific faults)";
CM_ SG_ 24 VCU_MTR_UV "VCU Fault State (0 for all clear; see value table for specific faults)";
CM_ SG_ 24 VCU_OTHER_FAULT "VCU Fault State (0 for all clear; see value table for specific faults)";
CM_ SG_ 24 VCU_MTR_DIR_CHANGE_LOCKOUT "VCU Fault State (0 for all clear; see value table for specific faults)";
CM_ SG_ 24 VCU_TIPPING_WARNING "VCU Fault State (0 for all clear; see value table for specific faults)";
CM_ SG_ 24 VCU_WARN_REGEN_NOT_ALLOW "VCU Fault State (0 for all clear; see value table for specific faults)";
CM_ SG_ 24 VCU_WARN_REGEN_NOT_EN "VCU Fault State (0 for all clear; see value table for specific faults)";
CM_ SG_ 32 BPS_Precharge_Battery_Voltage "Battery voltage as measured by active precharge circuitry";
CM_ SG_ 32 BPS_Precharge_Array_Voltage "Array voltage as measured by active precharge circuitry";
CM_ SG_ 33 VCU_Precharge_Battery_Voltage "Battery voltage as measured by active precharge circuitry";
CM_ SG_ 33 VCU_Precharge_Motor_Voltage "Motor controller DC bus voltage as measured by active precharge circuitry";
CM_ SG_ 80 AccelPedal_Main_Pos "Accelerator Pedal Position (Main Sensor)";
CM_ SG_ 80 AccelPedal_Redundant_Pos "Accelerator Pedal Position (Redundant Sensor)";
CM_ SG_ 80 BrakePedal_Main_Pos "Brake Pedal Position (Main Sensor)";
CM_ SG_ 80 BrakePedal_Redundant_Pos "Brake Pedal Position (Redundant Sensor)";
CM_ SG_ 80 AccelPedal_Main_Fault "Accelerator Pedal Main Sensor Fault (0 normal, 1 fault)";
CM_ SG_ 80 AccelPedal_Redundant_Fault "Accelerator Pedal Redundant Sensor Fault (0 normal, 1 fault)";
CM_ SG_ 80 BrakePedal_Main_Fault "Brake Pedal Main Sensor Fault (0 normal, 1 fault)";
CM_ SG_ 80 BrakePedal_Redundant_Fault "Brake Pedal Redundant Sensor Fault (0 normal, 1 fault)";
CM_ SG_ 80 Brake_Pressure_1_Fault "Brake Pressure Sensor 1 Fault (0 normal, 1 fault)";
CM_ SG_ 80 Brake_Pressure_2_Fault "Brake Pressure Sensor 1 Fault (0 normal, 1 fault)";
CM_ SG_ 96 Ignition_Array "Ignition Switch in Array Position";
CM_ SG_ 96 Ignition_Motor "Ignition Switch in Motor Position";
CM_ SG_ 96 Ignition_Off "Ignition Switch in Off Position";
CM_ SG_ 96 Cruise_Enable "Cruise Enable Button Pressed";
CM_ SG_ 96 Cruise_Set "Cruise Set Button Pressed";
CM_ SG_ 96 Gear_Forward "Gear Switch in Forward Position";
CM_ SG_ 96 Gear_Neutral "Gear Switch in Neutral Position";
CM_ SG_ 96 Gear_Reverse "Gear Switch in Reverse Position";
CM_ SG_ 96 Hazard_Pressed "Hazard Button Pressed";
CM_ SG_ 96 Horn_Pressed "Horn Button Pressed";
CM_ SG_ 96 Blinker_Left "Blinker Switch in Left Position";
CM_ SG_ 96 Blinker_Right "Blinker Switch in Right Position";
CM_ SG_ 96 PushToTalk_Pressed "Push To Talk (PTT) Button Pressed";
CM_ SG_ 96 Regen_Activate "Regen Activate Button Pressed";
CM_ SG_ 96 Regen_Enable "Regen Enable Button Pressed";
CM_ SG_ 768 Supplemental_Battery_Voltage "Supplemental Battery voltage in V";
CM_ SG_ 848 HSS_Channel_idx "High Side Switch Channel";
CM_ SG_ 848 HSS_Fault "High Side Switch Fault Status (0 normal, 1 faulted)";
CM_ SG_ 848 HSS_Enabled "High Side Switch Output Status (0 off, 1 on)";
CM_ SG_ 848 HSS_Measured_Voltage "High Side Switch Voltage";
CM_ SG_ 848 HSS_Measured_Current "High Side Switch Current";
CM_ SG_ 849 HSS_Channel_idx "High Side Switch Channel";
CM_ SG_ 849 HSS_SetSwitch "High Side Switch Control - Channel 1";
CM_ SG_ 850 HSS_Channel_idx "High Side Switch Channel";
CM_ SG_ 850 HSS_Current_Limit "High Side Switch Current Limit";
CM_ SG_ 1280 Pump_DutyCycle "Cooling Pump Duty Cycle";
CM_ SG_ 1280 Pump_Fault "Cooling Pump Fault (0 normal, 1 fault)";
CM_ SG_ 1280 FlowRate_1 "Cooling Loop Flow Rate Sensor 1 Measurement";
CM_ SG_ 1280 FlowRate_2 "Cooling Loop Flow Rate Sensor 2 Measurement";
CM_ SG_ 1281 Coolant_Temperature_1 "Cooling Loop Temperature Sensor 1 Measurement";
CM_ SG_ 1281 Coolant_Temperature_2 "Cooling Loop Temperature Sensor 2 Measurement";
CM_ SG_ 1282 Radiator_Fan_Speed_Measurement_1 "Measured Radiator Fan 1 Speed";
CM_ SG_ 1282 Radiator_Fan_Speed_Measurement_2 "Measured Radiator Fan 2 Speed";
CM_ SG_ 1282 Radiator_Fan_Speed_Target_1 "Target Radiator Fan 1 Speed";
CM_ SG_ 1282 Radiator_Fan_Speed_Target_2 "Target Radiator Fan 2 Speed";
CM_ SG_ 1536 LTC4421_HVDCDC_Selected "The LTC4421's channel selected signal for the HV DCDC";
CM_ SG_ 1616 Brake_Pressure "Brake Pressure PSI (Sensor 1)";
CM_ SG_ 1616 Brake_Pressure_ADC "Brake Pressure Raw Voltage (Sensor 1)";
CM_ SG_ 1617 Brake_Pressure "Brake Pressure PSI (Sensor 1)";
CM_ SG_ 1617 Brake_Pressure_ADC "Brake Pressure Raw Voltage (Sensor 1)";
CM_ SG_ 1664 Display_FrameRate "Dashboard Display Frame Rate (FPS)";
CM_ SG_ 1664 Camera_Status_Backup "Backup Camera Status (0 disconnected, 1 connected)";
CM_ SG_ 1664 Camera_Status_Left "Left Side View Camera Status (0 disconnected, 1 connected)";
CM_ SG_ 1664 Camera_Status_Right "Right Side View Camera Status (0 disconnected, 1 connected)";
CM_ SG_ 1872 BPS_Temperature_Tap_ADC "Raw thermistor voltage measurement for the specified VoltTemp and Tap ID";
CM_ SG_ 1875 BrakePedal_Main_ADC "Brake Pedal Raw Voltage Measurement (Main Sensor)";
CM_ SG_ 1875 BrakePedal_Redundant_ADC "Brake Pedal Raw Voltage Measurement (Redundant Sensor)";
CM_ SG_ 1876 AccelPedal_Main_ADC "Accelerator Pedal Raw Voltage Measurement (Main Sensor)";
CM_ SG_ 1876 AccelPedal_Redundant_ADC "Accelerator Pedal Raw Voltage Measurement (Redundant Sensor)";
CM_ SG_ 1056 MC_TritiumID "Device identifier. 0x00004003";
CM_ SG_ 1056 MC_SerialNumber "Device serial number, allocated at manufacture.";
CM_ SG_ 1057 MC_ActiveMotor "The index of the active motor currently being used.";
CM_ SG_ 1057 MC_TxErrorCount "The DSP CAN transmission error counter (CAN 2.0)";
CM_ SG_ 1057 MC_RxErrorCount "The DSP CAN receive error counter (CAN 2.0)";
CM_ SG_ 1058 MC_BusVoltage "DC bus voltage at the controller.";
CM_ SG_ 1058 MC_BusCurrent "Current drawn from the DC bus by the controller.";
CM_ SG_ 1059 MC_MotorVelocity "Motor angular frequency in revolutions per minute.";
CM_ SG_ 1059 MC_VehicleVelocity "Vehicle velocity in metres / second.";
CM_ SG_ 1060 MC_PhaseCurrentB "RMS current in motor Phase B.";
CM_ SG_ 1060 MC_PhaseCurrentC "RMS current in motor Phase C.";
CM_ SG_ 1061 MC_Vq "Imaginary component of the applied non-rotating voltage vector to the motor.";
CM_ SG_ 1061 MC_Vd "Real component of the applied non-rotating voltage vector to the motor.";
CM_ SG_ 1062 MC_Iq "Imaginary component of the applied non-rotating current vector to the motor. This current produces torque in the motor and should be in phase with the back-EMF of the motor";
CM_ SG_ 1062 MC_Id "Real component of the applied non-rotating current vector to the motor. This vector represents the field current of the motor.";
CM_ SG_ 1063 MC_BEMFq "The peak of the phase to neutral motor voltage.";
CM_ SG_ 1063 MC_BEMFd "By definition this value is always 0V.";
CM_ SG_ 1064 MC_Supply15V "Actual voltage level of the 15V power rail.";
CM_ SG_ 1065 MC_Supply1V9 "Actual voltage level of the 1.9V DSP power rail.";
CM_ SG_ 1065 MC_Supply3V3 "Actual voltage level of the 3.3V power rail.";
CM_ SG_ 1067 MC_MotorTemp "Internal temperature of the motor";
CM_ SG_ 1067 MC_HeatsinkTemp "Internal temperature of Heat-sink (case).";
CM_ SG_ 1068 MC_DspBoardTemp "Temperature of the DSP board.";
CM_ SG_ 1070 MC_TripOdometer "Distance the vehicle has travelled since reset.";
CM_ SG_ 1070 MC_DCBusAh "Charge flow into the controller DC bus from the time of reset.";
CM_ SG_ 1079 MC_SlipSpeed "Slip speed when driving an induction motor.";
CM_ BO_ 192 "Telem Leader Node";
CM_ SG_ 192 Timestamp "Wheel-Based Vehicle Speed: Speed of the vehicle as calculated from wheel or tailshaft speed.";

BA_DEF_  "DBName" STRING ;
BA_DEF_ BO_  "GenMsgSendType" ENUM  "Cyclic","Event","CyclicAndEvent","CyclicAndEventNoRepetition","None","Spontaneous";
BA_DEF_ BO_  "VFrameFormat" ENUM  "StandardCAN","ExtendedCAN","reserved","J1939PG","reserved","reserved","reserved","reserved","reserved","reserved","reserved","reserved","reserved","reserved","StandardCAN_FD","ExtendedCAN_FD";
BA_DEF_  "MultiplexExtEnabled" ENUM  "No","Yes";
BA_DEF_  "BusType" STRING ;
BA_DEF_ BO_  "CANFD_BRS" ENUM  "0","1";
BA_DEF_  "DatabaseVersion" STRING ;
BA_DEF_  "ProtocolType" STRING ;
BA_DEF_  "DatabaseCompiler" STRING ;
BA_DEF_DEF_  "DBName" "";
BA_DEF_DEF_  "GenMsgSendType" "Cyclic";
BA_DEF_DEF_  "VFrameFormat" "StandardCAN";
BA_DEF_DEF_  "MultiplexExtEnabled" "No";
BA_DEF_DEF_  "BusType" "";
BA_DEF_DEF_  "CANFD_BRS" "1";
BA_DEF_DEF_  "DatabaseVersion" "DEMO PLUS";
BA_DEF_DEF_  "ProtocolType" "";
BA_DEF_DEF_  "DatabaseCompiler" "";
BA_ "DBName" "HighNoon";
BA_ "BusType" "CAN";
BA_ "MultiplexExtEnabled" 1;
BA_ "BusType" "CAN FD";
BA_ "VFrameFormat" BO_ 2550588916 3;
BA_ "VFrameFormat" BO_ 2550589172 3;
BA_ "VFrameFormat" BO_ 2566869221 3;
BA_ "VFrameFormat" BO_ 4096 3;
BA_ "VFrameFormat" BO_ 4288 3;
BA_ "VFrameFormat" BO_ 4289 3;
BA_ "VFrameFormat" BO_ 4512 3;
BA_ "VFrameFormat" BO_ 4513 3;
BA_ "VFrameFormat" BO_ 4528 3;
BA_ "VFrameFormat" BO_ 4529 3;
BA_ "VFrameFormat" BO_ 4560 3;
BA_ "VFrameFormat" BO_ 4561 3;
BA_ "VFrameFormat" BO_ 4768 3;
BA_ "VFrameFormat" BO_ 4784 3;
BA_ "VFrameFormat" BO_ 4816 3;
BA_ "VFrameFormat" BO_ 5024 3;
BA_ "VFrameFormat" BO_ 5072 3;
BA_ "VFrameFormat" BO_ 5280 3;
BA_ "VFrameFormat" BO_ 5328 3;
BA_ "VFrameFormat" BO_ 5536 3;
BA_ "VFrameFormat" BO_ 5552 3;
BA_ "VFrameFormat" BO_ 5584 3;
BA_ "VFrameFormat" BO_ 6080 3;
BA_ "VFrameFormat" BO_ 6081 3;
BA_ "VFrameFormat" BO_ 6082 3;
BA_ "VFrameFormat" BO_ 6083 3;
BA_ "VFrameFormat" BO_ 6084 3;
BA_ "DatabaseCompiler" "CSS ELECTRONICS (WWW.CSSELECTRONICS.COM)";
BA_ "DatabaseVersion" "1.0.0";

VAL_ 2 BPS_Voltage_Tap_Fault 0 "OK" 1 "BQ I2C Read Error" 2 "Out-of-Bounds" 3 "Over-Voltage" 4 "Under-Voltage" 5 "Message Watchdog" ;
VAL_ 3 BPS_Voltage_Tap_Fault 0 "OK" 1 "BQ I2C Read Error" 2 "Out-of-Bounds" 3 "Over-Voltage" 4 "Under-Voltage" 5 "Message Watchdog" ;
VAL_ 4 BPS_Voltage_Tap_Fault 0 "OK" 1 "BQ I2C Read Error" 2 "Out-of-Bounds" 3 "Over-Voltage" 4 "Under-Voltage" 5 "Message Watchdog" ;
VAL_ 5 BPS_Voltage_Tap_Fault 0 "OK" 1 "BQ I2C Read Error" 2 "Out-of-Bounds" 3 "Over-Voltage" 4 "Under-Voltage" 5 "Message Watchdog" ;
VAL_ 6 BPS_Voltage_Tap_Fault 0 "OK" 1 "BQ I2C Read Error" 2 "Out-of-Bounds" 3 "Over-Voltage" 4 "Under-Voltage" 5 "Message Watchdog" ;
VAL_ 7 BPS_Voltage_Tap_Fault 0 "OK" 1 "BQ I2C Read Error" 2 "Out-of-Bounds" 3 "Over-Voltage" 4 "Under-Voltage" 5 "Message Watchdog" ;
VAL_ 8 BPS_Voltage_Tap_Fault 0 "OK" 1 "BQ I2C Read Error" 2 "Out-of-Bounds" 3 "Over-Voltage" 4 "Under-Voltage" 5 "Message Watchdog" ;
VAL_ 9 BPS_Voltage_Tap_Fault 0 "OK" 1 "BQ I2C Read Error" 2 "Out-of-Bounds" 3 "Over-Voltage" 4 "Under-Voltage" 5 "Message Watchdog" ;
VAL_ 10 BPS_Amperes_Fault 0 "OK" 1 "Out-of-Bounds" 2 "Over-Current (Discharge)" 3 "Over-Current (Charge)" 4 "Message Watchdog" ;
VAL_ 16 BPS_Temperature_Tap_Fault 0 "OK" 1 "Out-of-Bounds (Short to GND)" 2 "Out-of-Bounds (Short to VCC)" 3 "Disconnected" 4 "Over-Temperature" 5 "Charge Over-Temperature" 6 "Under-Temperature" 7 "Charge Under-Temperature" 8 "Message Watchdog" ;
VAL_ 17 BPS_Temperature_Tap_Fault 0 "OK" 1 "Out-of-Bounds (Short to GND)" 2 "Out-of-Bounds (Short to VCC)" 3 "Disconnected" 4 "Over-Temperature" 5 "Charge Over-Temperature" 6 "Under-Temperature" 7 "Charge Under-Temperature" 8 "Message Watchdog" ;
VAL_ 18 BPS_Temperature_Tap_Fault 0 "OK" 1 "Out-of-Bounds (Short to GND)" 2 "Out-of-Bounds (Short to VCC)" 3 "Disconnected" 4 "Over-Temperature" 5 "Charge Over-Temperature" 6 "Under-Temperature" 7 "Charge Under-Temperature" 8 "Message Watchdog" ;
VAL_ 19 BPS_Temperature_Tap_Fault 0 "OK" 1 "Out-of-Bounds (Short to GND)" 2 "Out-of-Bounds (Short to VCC)" 3 "Disconnected" 4 "Over-Temperature" 5 "Charge Over-Temperature" 6 "Under-Temperature" 7 "Charge Under-Temperature" 8 "Message Watchdog" ;
VAL_ 20 BPS_Temperature_Tap_Fault 0 "OK" 1 "Out-of-Bounds (Short to GND)" 2 "Out-of-Bounds (Short to VCC)" 3 "Disconnected" 4 "Over-Temperature" 5 "Charge Over-Temperature" 6 "Under-Temperature" 7 "Charge Under-Temperature" 8 "Message Watchdog" ;
VAL_ 21 BPS_Temperature_Tap_Fault 0 "OK" 1 "Out-of-Bounds (Short to GND)" 2 "Out-of-Bounds (Short to VCC)" 3 "Disconnected" 4 "Over-Temperature" 5 "Charge Over-Temperature" 6 "Under-Temperature" 7 "Charge Under-Temperature" 8 "Message Watchdog" ;
VAL_ 22 BPS_Temperature_Tap_Fault 0 "OK" 1 "Out-of-Bounds (Short to GND)" 2 "Out-of-Bounds (Short to VCC)" 3 "Disconnected" 4 "Over-Temperature" 5 "Charge Over-Temperature" 6 "Under-Temperature" 7 "Charge Under-Temperature" 8 "Message Watchdog" ;
VAL_ 23 BPS_Temperature_Tap_Fault 0 "OK" 1 "Out-of-Bounds (Short to GND)" 2 "Out-of-Bounds (Short to VCC)" 3 "Disconnected" 4 "Over-Temperature" 5 "Charge Over-Temperature" 6 "Under-Temperature" 7 "Charge Under-Temperature" 8 "Message Watchdog" ;
VAL_ 1 BPS_Fault 0 "OK" 1 "Overvoltage" 2 "Undervoltage" 3 "Regen" 4 "Overtemperature" 5 "Elcon" 6 "Array Precharge Timeout" 7 "Internal Watchdog" 8 "Segment Watchdog" 9 "HV Plus Contactor Sense" 10 "HV Minus Contactor Sense" 11 "Array Contactor Sense" 12 "Array Pchg Contactor Sense" 13 "Estop 1" 14 "Estop 2" 15 "Estop 3" 16 "Charging Overcurrent" 17 "Discharging Overcurrent" 18 "Amperes Watchdog" ;
VAL_ 1 BPS_Charge_OK 0 "NOT OK" 1 "OK" ;
VAL_ 1 BPS_Regen_OK 0 "NOT OK" 1 "OK" ;
VAL_ 1 HV_Plus_Contactor_State 0 "Open" 1 "Closed" ;
VAL_ 1 HV_Minus_Contactor_State 0 "Open" 1 "Closed" ;
VAL_ 1 Array_Contactor_State 0 "Open" 1 "Closed" ;
VAL_ 1 Array_Precharge_Contactor_State 0 "Open" 1 "Closed" ;
VAL_ 1 BPS_Segment0_Status 0 "OK" 1 "FAULT" ;
VAL_ 1 BPS_Segment1_Status 0 "OK" 1 "FAULT" ;
VAL_ 1 BPS_Segment2_Status 0 "OK" 1 "FAULT" ;
VAL_ 1 BPS_Segment3_Status 0 "OK" 1 "FAULT" ;
VAL_ 1 BPS_Segment4_Status 0 "OK" 1 "FAULT" ;
VAL_ 1 BPS_Segment5_Status 0 "OK" 1 "FAULT" ;
VAL_ 1 BPS_Segment6_Status 0 "OK" 1 "FAULT" ;
VAL_ 1 BPS_Segment7_Status 0 "OK" 1 "FAULT" ;
VAL_ 11 BPS_Voltage_Tap_Fault 0 "OK" 1 "BQ I2C Read Error" 2 "Out-of-Bounds" 3 "Over-Voltage" 4 "Under-Voltage" 5 "Message Watchdog" ;
VAL_ 12 BPS_Temperature_Tap_Fault 0 "OK" 1 "Out-of-Bounds (Short to GND)" 2 "Out-of-Bounds (Short to VCC)" 3 "Disconnected" 4 "Over-Temperature" 5 "Charge Over-Temperature" 6 "Under-Temperature" 7 "Charge Under-Temperature" 8 "Message Watchdog" ;
VAL_ 14 Elcon_HW_FAULT 0 "OK" 1 "FAULT" ;
VAL_ 14 Elcon_OVER_TEMPERATURE 0 "OK" 1 "FAULT" ;
VAL_ 14 Elcon_INPUT_VOL_ERROR 0 "OK" 1 "FAULT" ;
VAL_ 14 Elcon_START_STATE 0 "NOT OK" 1 "OK" ;
VAL_ 14 Elcon_CMD_TIMEOUT 0 "NOT OK" 1 "OK" ;
VAL_ 14 Elcon_Watchdog 0 "NOT OK" 1 "OK" ;
VAL_ 24 VCU_FSM_State 0 "INIT" 1 "FORWARD_DRIVE" 2 "NEUTRAL_DRIVE" 3 "REVERSE_DRIVE" 4 "REGEN" 5 "CRUISE_CONTROL" 6 "DISABLED" 7 "VEHICLE_NOT_READY" ;
VAL_ 24 Motor_Ready 0 "NOT OK" 1 "OK" ;
VAL_ 24 Motor_Precharge_Contactor_State 0 "Open" 1 "Closed" ;
VAL_ 24 Motor_Contactor_State 0 "Open" 1 "Closed" ;
VAL_ 24 VCU_Driver_Input_Watchdog 0 "NOT OK" 1 "OK" ;
VAL_ 24 VCU_Pedals_Watchdog 0 "NOT OK" 1 "OK" ;
VAL_ 24 VCU_BPS_Watchdog 0 "NOT OK" 1 "OK" ;
VAL_ 24 VCU_Steering_Angle_Watchdog 0 "NOT OK" 1 "OK" ;
VAL_ 24 VCU_BPS_FAULT_DETECTED 0 "OK" 1 "FAULT" ;
VAL_ 24 VCU_CONTROLS_FAULT_DETECTED 0 "OK" 1 "FAULT" ;
VAL_ 24 VCU_MTR_FAULT_DETECTED 0 "OK" 1 "FAULT" ;
VAL_ 24 VCU_PEDALS_FAULT_DETECTED 0 "OK" 1 "FAULT" ;
VAL_ 24 VCU_STEERING_FAULT_DETECTED 0 "OK" 1 "FAULT" ;
VAL_ 24 VCU_MotorCommandSource 0 "VCU" 1 "Tritium External" ;
VAL_ 24 VCU_Regen_Active 0 "Inactive" 1 "Active" ;
VAL_ 24 VCU_Regen_OK 0 "NOT OK" 1 "OK" ;
VAL_ 24 VCU_MTR_PCHG_TIMEOUT 0 "OK" 1 "FAULT" ;
VAL_ 24 VCU_MTR_PCHG_CONT_TIMEOUT 0 "OK" 1 "FAULT" ;
VAL_ 24 VCU_MTR_PCHG_CONT_MISMATCH 0 "OK" 1 "FAULT" ;
VAL_ 24 VCU_MTR_CONT_MISMATCH 0 "OK" 1 "FAULT" ;
VAL_ 24 VCU_MTR_CONT_TIMEOUT 0 "OK" 1 "FAULT" ;
VAL_ 24 VCU_PCHG_OV 0 "OK" 1 "FAULT" ;
VAL_ 24 VCU_PCHG_UV 0 "OK" 1 "FAULT" ;
VAL_ 24 VCU_MTR_OV 0 "OK" 1 "FAULT" ;
VAL_ 24 VCU_MTR_UV 0 "OK" 1 "FAULT" ;
VAL_ 24 VCU_OTHER_FAULT 0 "OK" 1 "FAULT" ;
VAL_ 24 VCU_MTR_DIR_CHANGE_LOCKOUT 0 "Inactive" 1 "Active" ;
VAL_ 24 VCU_TIPPING_WARNING 0 "Inactive" 1 "Active" ;
VAL_ 24 VCU_WARN_REGEN_NOT_ALLOW 0 "Inactive" 1 "Active" ;
VAL_ 24 VCU_WARN_REGEN_NOT_EN 0 "Inactive" 1 "Active" ;
VAL_ 24 VCU_FSM_INP_BRAKE 0 "False" 1 "True" ;
VAL_ 24 VCU_FSM_INP_PCHG_OK 0 "False" 1 "True" ;
VAL_ 24 VCU_FSM_INP_CRUISE_REQ 0 "False" 1 "True" ;
VAL_ 24 VCU_FSM_INP_REGEN_REQ 0 "False" 1 "True" ;
VAL_ 24 VCU_FSM_INP_REGEN_ENABLE 0 "False" 1 "True" ;
VAL_ 24 VCU_FSM_INP_REGEN_RDY 0 "False" 1 "True" ;
VAL_ 24 VCU_FSM_INP_FORWARD 0 "False" 1 "True" ;
VAL_ 24 VCU_FSM_INP_NEUTRAL 0 "False" 1 "True" ;
VAL_ 24 VCU_FSM_INP_REVERSE 0 "False" 1 "True" ;
VAL_ 25 Controls_Leader_Fault 0 "OK" 1 "Bosch LWS Watchdog" 2 "BPS Watchdog" 3 "Invalid Driver Inputs" 4 "Lighting Board Fault" 5 "Lighting Board Watchdog" ;
VAL_ 25 LightingBoard_Front_Status 0 "OK" 1 "Addr LED Undercurrent" 2 "LED0 Undercurrent" 3 "LED1 Undercurrent" 4 "Addr LED Overcurrent" 5 "LED0 Overcurrent" 6 "LED1 Overcurrent" 7 "Light Command Watchdog" 8 "Watchdog" ;
VAL_ 25 LightingBoard_Left_Status 0 "OK" 1 "Addr LED Undercurrent" 2 "LED0 Undercurrent" 3 "LED1 Undercurrent" 4 "Addr LED Overcurrent" 5 "LED0 Overcurrent" 6 "LED1 Overcurrent" 7 "Light Command Watchdog" 8 "Watchdog" ;
VAL_ 25 LightingBoard_Right_Status 0 "OK" 1 "Addr LED Undercurrent" 2 "LED0 Undercurrent" 3 "LED1 Undercurrent" 4 "Addr LED Overcurrent" 5 "LED0 Overcurrent" 6 "LED1 Overcurrent" 7 "Light Command Watchdog" 8 "Watchdog" ;
VAL_ 25 LightingBoard_Rear_Status 0 "OK" 1 "Addr LED Undercurrent" 2 "LED0 Undercurrent" 3 "LED1 Undercurrent" 4 "Addr LED Overcurrent" 5 "LED0 Overcurrent" 6 "LED1 Overcurrent" 7 "Light Command Watchdog" 8 "Watchdog" ;
VAL_ 25 LightingBoard_Canopy_Status 0 "OK" 1 "Addr LED Undercurrent" 2 "LED0 Undercurrent" 3 "LED1 Undercurrent" 4 "Addr LED Overcurrent" 5 "LED0 Overcurrent" 6 "LED1 Overcurrent" 7 "Light Command Watchdog" 8 "Watchdog" ;
VAL_ 80 AccelPedal_Main_Fault 0 "OK" 1 "FAULT" ;
VAL_ 80 AccelPedal_Redundant_Fault 0 "OK" 1 "FAULT" ;
VAL_ 80 BrakePedal_Main_Fault 0 "OK" 1 "FAULT" ;
VAL_ 80 BrakePedal_Redundant_Fault 0 "OK" 1 "FAULT" ;
VAL_ 80 Brake_Pressure_1_Fault 0 "OK" 1 "FAULT" ;
VAL_ 80 Brake_Pressure_2_Fault 0 "OK" 1 "FAULT" ;
VAL_ 96 Ignition_Array 0 "-" 1 "Selected" ;
VAL_ 96 Ignition_Motor 0 "-" 1 "Selected" ;
VAL_ 96 Ignition_Off 0 "-" 1 "Selected" ;
VAL_ 96 Cruise_Enable 0 "Disabled" 1 "Enabled" ;
VAL_ 96 Cruise_Set 0 "-" 1 "Pressed" ;
VAL_ 96 Gear_Forward 0 "-" 1 "Selected" ;
VAL_ 96 Gear_Neutral 0 "-" 1 "Selected" ;
VAL_ 96 Gear_Reverse 0 "-" 1 "Selected" ;
VAL_ 96 Hazard_Pressed 0 "Off" 1 "On" ;
VAL_ 96 Horn_Pressed 0 "Off" 1 "On" ;
VAL_ 96 Blinker_Left 0 "-" 1 "Selected" ;
VAL_ 96 Blinker_Right 0 "-" 1 "Selected" ;
VAL_ 96 PushToTalk_Pressed 0 "-" 1 "Pressed" ;
VAL_ 96 Regen_Activate 0 "-" 1 "Pressed" ;
VAL_ 96 Regen_Enable 0 "Disabled" 1 "Enabled" ;
VAL_ 103 BPS_Drive_Profile_Enable_Master 0 "Disabled" 1 "Enabled" ;
VAL_ 103 BPS_Regen_Allow 0 "False" 1 "True" ;
VAL_ 103 BPS_Adv_MPPT_Control 0 "Disabled" 1 "Enabled" ;
VAL_ 103 BPS_Soft_Shdn 0 "Disabled" 1 "Enabled" ;
VAL_ 103 BPS_Vsag_Compensation 0 "Disabled" 1 "Enabled" ;
VAL_ 105 Module0_Override 0 "NORMAL_OPERATION" 1 "VOLTAGE_OVERRIDE" 2 "TEMP_OVERRIDE" 3 "OVERRIDE_ALL" ;
VAL_ 105 Module1_Override 0 "NORMAL_OPERATION" 1 "VOLTAGE_OVERRIDE" 2 "TEMP_OVERRIDE" 3 "OVERRIDE_ALL" ;
VAL_ 105 Module2_Override 0 "NORMAL_OPERATION" 1 "VOLTAGE_OVERRIDE" 2 "TEMP_OVERRIDE" 3 "OVERRIDE_ALL" ;
VAL_ 105 Module3_Override 0 "NORMAL_OPERATION" 1 "VOLTAGE_OVERRIDE" 2 "TEMP_OVERRIDE" 3 "OVERRIDE_ALL" ;
VAL_ 105 Module4_Override 0 "NORMAL_OPERATION" 1 "VOLTAGE_OVERRIDE" 2 "TEMP_OVERRIDE" 3 "OVERRIDE_ALL" ;
VAL_ 105 Module5_Override 0 "NORMAL_OPERATION" 1 "VOLTAGE_OVERRIDE" 2 "TEMP_OVERRIDE" 3 "OVERRIDE_ALL" ;
VAL_ 105 Module6_Override 0 "NORMAL_OPERATION" 1 "VOLTAGE_OVERRIDE" 2 "TEMP_OVERRIDE" 3 "OVERRIDE_ALL" ;
VAL_ 105 Module7_Override 0 "NORMAL_OPERATION" 1 "VOLTAGE_OVERRIDE" 2 "TEMP_OVERRIDE" 3 "OVERRIDE_ALL" ;
VAL_ 105 Module8_Override 0 "NORMAL_OPERATION" 1 "VOLTAGE_OVERRIDE" 2 "TEMP_OVERRIDE" 3 "OVERRIDE_ALL" ;
VAL_ 105 Module9_Override 0 "NORMAL_OPERATION" 1 "VOLTAGE_OVERRIDE" 2 "TEMP_OVERRIDE" 3 "OVERRIDE_ALL" ;
VAL_ 105 Module10_Override 0 "NORMAL_OPERATION" 1 "VOLTAGE_OVERRIDE" 2 "TEMP_OVERRIDE" 3 "OVERRIDE_ALL" ;
VAL_ 105 Module11_Override 0 "NORMAL_OPERATION" 1 "VOLTAGE_OVERRIDE" 2 "TEMP_OVERRIDE" 3 "OVERRIDE_ALL" ;
VAL_ 105 Module12_Override 0 "NORMAL_OPERATION" 1 "VOLTAGE_OVERRIDE" 2 "TEMP_OVERRIDE" 3 "OVERRIDE_ALL" ;
VAL_ 105 Module13_Override 0 "NORMAL_OPERATION" 1 "VOLTAGE_OVERRIDE" 2 "TEMP_OVERRIDE" 3 "OVERRIDE_ALL" ;
VAL_ 105 Module14_Override 0 "NORMAL_OPERATION" 1 "VOLTAGE_OVERRIDE" 2 "TEMP_OVERRIDE" 3 "OVERRIDE_ALL" ;
VAL_ 105 Module15_Override 0 "NORMAL_OPERATION" 1 "VOLTAGE_OVERRIDE" 2 "TEMP_OVERRIDE" 3 "OVERRIDE_ALL" ;
VAL_ 105 Module16_Override 0 "NORMAL_OPERATION" 1 "VOLTAGE_OVERRIDE" 2 "TEMP_OVERRIDE" 3 "OVERRIDE_ALL" ;
VAL_ 105 Module17_Override 0 "NORMAL_OPERATION" 1 "VOLTAGE_OVERRIDE" 2 "TEMP_OVERRIDE" 3 "OVERRIDE_ALL" ;
VAL_ 105 Module18_Override 0 "NORMAL_OPERATION" 1 "VOLTAGE_OVERRIDE" 2 "TEMP_OVERRIDE" 3 "OVERRIDE_ALL" ;
VAL_ 105 Module19_Override 0 "NORMAL_OPERATION" 1 "VOLTAGE_OVERRIDE" 2 "TEMP_OVERRIDE" 3 "OVERRIDE_ALL" ;
VAL_ 105 Module20_Override 0 "NORMAL_OPERATION" 1 "VOLTAGE_OVERRIDE" 2 "TEMP_OVERRIDE" 3 "OVERRIDE_ALL" ;
VAL_ 105 Module21_Override 0 "NORMAL_OPERATION" 1 "VOLTAGE_OVERRIDE" 2 "TEMP_OVERRIDE" 3 "OVERRIDE_ALL" ;
VAL_ 105 Module22_Override 0 "NORMAL_OPERATION" 1 "VOLTAGE_OVERRIDE" 2 "TEMP_OVERRIDE" 3 "OVERRIDE_ALL" ;
VAL_ 105 Module23_Override 0 "NORMAL_OPERATION" 1 "VOLTAGE_OVERRIDE" 2 "TEMP_OVERRIDE" 3 "OVERRIDE_ALL" ;
VAL_ 105 Module24_Override 0 "NORMAL_OPERATION" 1 "VOLTAGE_OVERRIDE" 2 "TEMP_OVERRIDE" 3 "OVERRIDE_ALL" ;
VAL_ 105 Module25_Override 0 "NORMAL_OPERATION" 1 "VOLTAGE_OVERRIDE" 2 "TEMP_OVERRIDE" 3 "OVERRIDE_ALL" ;
VAL_ 105 Module26_Override 0 "NORMAL_OPERATION" 1 "VOLTAGE_OVERRIDE" 2 "TEMP_OVERRIDE" 3 "OVERRIDE_ALL" ;
VAL_ 105 Module27_Override 0 "NORMAL_OPERATION" 1 "VOLTAGE_OVERRIDE" 2 "TEMP_OVERRIDE" 3 "OVERRIDE_ALL" ;
VAL_ 105 Module28_Override 0 "NORMAL_OPERATION" 1 "VOLTAGE_OVERRIDE" 2 "TEMP_OVERRIDE" 3 "OVERRIDE_ALL" ;
VAL_ 105 Module29_Override 0 "NORMAL_OPERATION" 1 "VOLTAGE_OVERRIDE" 2 "TEMP_OVERRIDE" 3 "OVERRIDE_ALL" ;
VAL_ 105 Module30_Override 0 "NORMAL_OPERATION" 1 "VOLTAGE_OVERRIDE" 2 "TEMP_OVERRIDE" 3 "OVERRIDE_ALL" ;
VAL_ 105 Module31_Override 0 "NORMAL_OPERATION" 1 "VOLTAGE_OVERRIDE" 2 "TEMP_OVERRIDE" 3 "OVERRIDE_ALL" ;
VAL_ 513 MPPT_Mode 0 "Constant Input Voltage" 1 "Constant Input Current" 2 "Minimum Input Current" 3 "Constant Output Voltage" 4 "Constant Output Current" 5 "Temperature De-Rating" 6 "FAULT" ;
VAL_ 513 MPPT_Fault 0 "OK" 1 "Configuration Error" 2 "Input Over Voltage" 3 "Output Over Voltage" 4 "Output Over Current" 5 "Input Over Current" 6 "Input Under Current" 7 "Phase Over Current" 8 "Unknown Fault" ;
VAL_ 513 MPPT_Enabled 0 "Disabled" 1 "Enabled" 2 "Enabled - Constant Voltage" ;
VAL_ 521 MPPT_Set_Enable 0 "Disabled" 1 "Enabled" 2 "Enabled - Constant Voltage" ;
VAL_ 545 MPPT_Mode 0 "Constant Input Voltage" 1 "Constant Input Current" 2 "Minimum Input Current" 3 "Constant Output Voltage" 4 "Constant Output Current" 5 "Temperature De-Rating" 6 "FAULT" ;
VAL_ 545 MPPT_Fault 0 "OK" 1 "Configuration Error" 2 "Input Over Voltage" 3 "Output Over Voltage" 4 "Output Over Current" 5 "Input Over Current" 6 "Input Under Current" 7 "Phase Over Current" 8 "Unknown Fault" ;
VAL_ 545 MPPT_Enabled 0 "Disabled" 1 "Enabled" 2 "Enabled - Constant Voltage" ;
VAL_ 553 MPPT_Set_Enable 0 "Disabled" 1 "Enabled" 2 "Enabled - Constant Voltage" ;
VAL_ 577 MPPT_Mode 0 "Constant Input Voltage" 1 "Constant Input Current" 2 "Minimum Input Current" 3 "Constant Output Voltage" 4 "Constant Output Current" 5 "Temperature De-Rating" 6 "FAULT" ;
VAL_ 577 MPPT_Fault 0 "OK" 1 "Configuration Error" 2 "Input Over Voltage" 3 "Output Over Voltage" 4 "Output Over Current" 5 "Input Over Current" 6 "Input Under Current" 7 "Phase Over Current" 8 "Unknown Fault" ;
VAL_ 577 MPPT_Enabled 0 "Disabled" 1 "Enabled" 2 "Enabled - Constant Voltage" ;
VAL_ 585 MPPT_Set_Enable 0 "Disabled" 1 "Enabled" 2 "Enabled - Constant Voltage" ;
VAL_ 768 Supplemental_Battery_Fault 0 "OK" 1 "Under-Voltage" 2 "Over-Voltage" 3 "Over-Current (Discharge)" 4 "Over-Current (Charge)" 5 "Unknown Fault" ;
VAL_ 769 Supplemental_Charger_Status 0 "Charge Disabled" 1 "Trickle Charging" 2 "Precharge" 3 "Fast Charging" 4 "Taper" 5 "ERROR" 6 "Topping Off" 7 "Done" ;
VAL_ 769 BQ25756E_Error 0 "OK" 1 "i2c_error" 2 "Input_UV" 3 "Input_OV" 4 "Battery_OC" 5 "Battery_OV" 6 "Over-Temperature" ;
VAL_ 769 BQ25756E_Watchdog 0 "NOT OK" 1 "OK" ;
VAL_ 848 HSS_Channel_idx 0 "VCU" 1 "Dashboard" 2 "Horn" 3 "Lights" 4 "Pi + Display" 5 "Pedals" 6 "Cameras" 7 "Unassigned_0" 8 "Battery" 9 "MPPTs" 10 "Motor Controller" 11 "Telemetry + Data Acq" 12 "Pump" 13 "Unassigned_1" 14 "Unassigned_2" 15 "PDE Fans" ;
VAL_ 848 HSS_Fault 0 "OK" 1 "FAULT" ;
VAL_ 848 HSS_Enabled 0 "Disabled" 1 "Enabled" ;
VAL_ 849 HSS_Channel_idx 0 "VCU" 1 "Dashboard" 2 "Horn" 3 "Lights" 4 "Pi + Display" 5 "Pedals" 6 "Cameras" 7 "Unassigned_0" 8 "Battery" 9 "MPPTs" 10 "Motor Controller" 11 "Telemetry + Data Acq" 12 "Pump" 13 "Unassigned_1" 14 "Unassigned_2" 15 "PDE Fans" ;
VAL_ 849 HSS_SetSwitch 0 "Do Nothing" 1 "Toggle On" 2 "Toggle Off" ;
VAL_ 850 HSS_Channel_idx 0 "VCU" 1 "Dashboard" 2 "Horn" 3 "Lights" 4 "Pi + Display" 5 "Pedals" 6 "Cameras" 7 "Unassigned_0" 8 "Battery" 9 "MPPTs" 10 "Motor Controller" 11 "Telemetry + Data Acq" 12 "Pump" 13 "Unassigned_1" 14 "Unassigned_2" 15 "PDE Fans" ;
VAL_ 1280 Pump_Fault 0 "OK" 1 "FAULT" ;
VAL_ 1536 LTC4421_HVDCDC_Selected 0 "-" 1 "Selected" ;
VAL_ 1536 LTC4421_HVDCDC_Fault 0 "OK" 1 "FAULT" ;
VAL_ 1536 LTC4421_HVDCDC_Valid 0 "NOT OK" 1 "OK" ;
VAL_ 1536 LTC4421_SuppBatt_Selected 0 "-" 1 "Selected" ;
VAL_ 1536 LTC4421_SuppBatt_Fault 0 "OK" 1 "FAULT" ;
VAL_ 1536 LTC4421_SuppBatt_Valid 0 "NOT OK" 1 "OK" ;
VAL_ 1536 LV_EN_SupplementalBattery 0 "Disabled" 1 "Enabled" ;
VAL_ 1536 LV_EN_PowerSupply 0 "Disabled" 1 "Enabled" ;
VAL_ 1639 BPS_Drive_Profile_Enable_Master 0 "Disabled" 1 "Enabled" ;
VAL_ 1639 BPS_Regen_Allow 0 "False" 1 "True" ;
VAL_ 1639 BPS_Adv_MPPT_Control 0 "Disabled" 1 "Enabled" ;
VAL_ 1639 BPS_Soft_Shdn 0 "Disabled" 1 "Enabled" ;
VAL_ 1639 BPS_Vsag_Compensation 0 "Disabled" 1 "Enabled" ;
VAL_ 1641 Module0_Override 0 "NORMAL_OPERATION" 1 "VOLTAGE_OVERRIDE" 2 "TEMP_OVERRIDE" 3 "OVERRIDE_ALL" ;
VAL_ 1641 Module1_Override 0 "NORMAL_OPERATION" 1 "VOLTAGE_OVERRIDE" 2 "TEMP_OVERRIDE" 3 "OVERRIDE_ALL" ;
VAL_ 1641 Module2_Override 0 "NORMAL_OPERATION" 1 "VOLTAGE_OVERRIDE" 2 "TEMP_OVERRIDE" 3 "OVERRIDE_ALL" ;
VAL_ 1641 Module3_Override 0 "NORMAL_OPERATION" 1 "VOLTAGE_OVERRIDE" 2 "TEMP_OVERRIDE" 3 "OVERRIDE_ALL" ;
VAL_ 1641 Module4_Override 0 "NORMAL_OPERATION" 1 "VOLTAGE_OVERRIDE" 2 "TEMP_OVERRIDE" 3 "OVERRIDE_ALL" ;
VAL_ 1641 Module5_Override 0 "NORMAL_OPERATION" 1 "VOLTAGE_OVERRIDE" 2 "TEMP_OVERRIDE" 3 "OVERRIDE_ALL" ;
VAL_ 1641 Module6_Override 0 "NORMAL_OPERATION" 1 "VOLTAGE_OVERRIDE" 2 "TEMP_OVERRIDE" 3 "OVERRIDE_ALL" ;
VAL_ 1641 Module7_Override 0 "NORMAL_OPERATION" 1 "VOLTAGE_OVERRIDE" 2 "TEMP_OVERRIDE" 3 "OVERRIDE_ALL" ;
VAL_ 1641 Module8_Override 0 "NORMAL_OPERATION" 1 "VOLTAGE_OVERRIDE" 2 "TEMP_OVERRIDE" 3 "OVERRIDE_ALL" ;
VAL_ 1641 Module9_Override 0 "NORMAL_OPERATION" 1 "VOLTAGE_OVERRIDE" 2 "TEMP_OVERRIDE" 3 "OVERRIDE_ALL" ;
VAL_ 1641 Module10_Override 0 "NORMAL_OPERATION" 1 "VOLTAGE_OVERRIDE" 2 "TEMP_OVERRIDE" 3 "OVERRIDE_ALL" ;
VAL_ 1641 Module11_Override 0 "NORMAL_OPERATION" 1 "VOLTAGE_OVERRIDE" 2 "TEMP_OVERRIDE" 3 "OVERRIDE_ALL" ;
VAL_ 1641 Module12_Override 0 "NORMAL_OPERATION" 1 "VOLTAGE_OVERRIDE" 2 "TEMP_OVERRIDE" 3 "OVERRIDE_ALL" ;
VAL_ 1641 Module13_Override 0 "NORMAL_OPERATION" 1 "VOLTAGE_OVERRIDE" 2 "TEMP_OVERRIDE" 3 "OVERRIDE_ALL" ;
VAL_ 1641 Module14_Override 0 "NORMAL_OPERATION" 1 "VOLTAGE_OVERRIDE" 2 "TEMP_OVERRIDE" 3 "OVERRIDE_ALL" ;
VAL_ 1641 Module15_Override 0 "NORMAL_OPERATION" 1 "VOLTAGE_OVERRIDE" 2 "TEMP_OVERRIDE" 3 "OVERRIDE_ALL" ;
VAL_ 1641 Module16_Override 0 "NORMAL_OPERATION" 1 "VOLTAGE_OVERRIDE" 2 "TEMP_OVERRIDE" 3 "OVERRIDE_ALL" ;
VAL_ 1641 Module17_Override 0 "NORMAL_OPERATION" 1 "VOLTAGE_OVERRIDE" 2 "TEMP_OVERRIDE" 3 "OVERRIDE_ALL" ;
VAL_ 1641 Module18_Override 0 "NORMAL_OPERATION" 1 "VOLTAGE_OVERRIDE" 2 "TEMP_OVERRIDE" 3 "OVERRIDE_ALL" ;
VAL_ 1641 Module19_Override 0 "NORMAL_OPERATION" 1 "VOLTAGE_OVERRIDE" 2 "TEMP_OVERRIDE" 3 "OVERRIDE_ALL" ;
VAL_ 1641 Module20_Override 0 "NORMAL_OPERATION" 1 "VOLTAGE_OVERRIDE" 2 "TEMP_OVERRIDE" 3 "OVERRIDE_ALL" ;
VAL_ 1641 Module21_Override 0 "NORMAL_OPERATION" 1 "VOLTAGE_OVERRIDE" 2 "TEMP_OVERRIDE" 3 "OVERRIDE_ALL" ;
VAL_ 1641 Module22_Override 0 "NORMAL_OPERATION" 1 "VOLTAGE_OVERRIDE" 2 "TEMP_OVERRIDE" 3 "OVERRIDE_ALL" ;
VAL_ 1641 Module23_Override 0 "NORMAL_OPERATION" 1 "VOLTAGE_OVERRIDE" 2 "TEMP_OVERRIDE" 3 "OVERRIDE_ALL" ;
VAL_ 1641 Module24_Override 0 "NORMAL_OPERATION" 1 "VOLTAGE_OVERRIDE" 2 "TEMP_OVERRIDE" 3 "OVERRIDE_ALL" ;
VAL_ 1641 Module25_Override 0 "NORMAL_OPERATION" 1 "VOLTAGE_OVERRIDE" 2 "TEMP_OVERRIDE" 3 "OVERRIDE_ALL" ;
VAL_ 1641 Module26_Override 0 "NORMAL_OPERATION" 1 "VOLTAGE_OVERRIDE" 2 "TEMP_OVERRIDE" 3 "OVERRIDE_ALL" ;
VAL_ 1641 Module27_Override 0 "NORMAL_OPERATION" 1 "VOLTAGE_OVERRIDE" 2 "TEMP_OVERRIDE" 3 "OVERRIDE_ALL" ;
VAL_ 1641 Module28_Override 0 "NORMAL_OPERATION" 1 "VOLTAGE_OVERRIDE" 2 "TEMP_OVERRIDE" 3 "OVERRIDE_ALL" ;
VAL_ 1641 Module29_Override 0 "NORMAL_OPERATION" 1 "VOLTAGE_OVERRIDE" 2 "TEMP_OVERRIDE" 3 "OVERRIDE_ALL" ;
VAL_ 1641 Module30_Override 0 "NORMAL_OPERATION" 1 "VOLTAGE_OVERRIDE" 2 "TEMP_OVERRIDE" 3 "OVERRIDE_ALL" ;
VAL_ 1641 Module31_Override 0 "NORMAL_OPERATION" 1 "VOLTAGE_OVERRIDE" 2 "TEMP_OVERRIDE" 3 "OVERRIDE_ALL" ;
VAL_ 1664 Camera_Status_Backup 0 "NOT OK" 1 "OK" ;
VAL_ 1664 Camera_Status_Left 0 "NOT OK" 1 "OK" ;
VAL_ 1664 Camera_Status_Right 0 "NOT OK" 1 "OK" ;
VAL_ 2550589172 Elcon_MuxPage 1 "Page 1" 2 "Page 2" 3 "Page 3" 4 "Page 4" 5 "Page 5" ;
VAL_ 2566869221 Elcon_HW_FAULT 0 "OK" 1 "FAULT" ;
VAL_ 2566869221 Elcon_OVER_TEMPERATURE 0 "OK" 1 "FAULT" ;
VAL_ 2566869221 Elcon_INPUT_VOL_ERROR 0 "OK" 1 "FAULT" ;
VAL_ 2566869221 Elcon_START_STATE 0 "NOT OK" 1 "OK" ;
VAL_ 2566869221 Elcon_CMD_TIMEOUT 0 "NOT OK" 1 "OK" ;
VAL_ 1632 Lighting_Set_Headlights 0 "Off" 1 "On" ;
VAL_ 1632 Lighting_Set_Left_Indicator 0 "Off" 1 "On" ;
VAL_ 1632 Lighting_Set_Right_Indicator 0 "Off" 1 "On" ;
VAL_ 1632 Lighting_Set_Brake 0 "Off" 1 "On" ;
VAL_ 1632 Lighting_Set_BPS_Strobe 0 "Off" 1 "On" ;
VAL_ 1632 Lighting_Set_Custom_Mode 0 "Off" 1 "Mode 1 Active" 2 "Mode 2 Active" 3 "Mode 3 Active" ;
VAL_ 1648 Lighting_Board_Fault 0 "OK" 1 "Addr LED Undercurrent" 2 "LED0 Undercurrent" 3 "LED1 Undercurrent" 4 "Addr LED Overcurrent" 5 "LED0 Overcurrent" 6 "LED1 Overcurrent" 7 "Light Command Watchdog" 8 "Watchdog" ;
VAL_ 1648 Light_Headlight 0 "Off" 1 "On" ;
VAL_ 1648 Light_Left_Indicator 0 "Off" 1 "On" ;
VAL_ 1648 Light_Right_Indicator 0 "Off" 1 "On" ;
VAL_ 1648 Light_BPS_Strobe 0 "Off" 1 "On" ;
VAL_ 1648 Light_Brakelight 0 "Off" 1 "On" ;
VAL_ 1648 Light_CustomMode 0 "Off" 1 "On" ;
VAL_ 1649 Lighting_Board_Fault 0 "OK" 1 "Addr LED Undercurrent" 2 "LED0 Undercurrent" 3 "LED1 Undercurrent" 4 "Addr LED Overcurrent" 5 "LED0 Overcurrent" 6 "LED1 Overcurrent" 7 "Light Command Watchdog" 8 "Watchdog" ;
VAL_ 1649 Light_Headlight 0 "Off" 1 "On" ;
VAL_ 1649 Light_Left_Indicator 0 "Off" 1 "On" ;
VAL_ 1649 Light_Right_Indicator 0 "Off" 1 "On" ;
VAL_ 1649 Light_BPS_Strobe 0 "Off" 1 "On" ;
VAL_ 1649 Light_Brakelight 0 "Off" 1 "On" ;
VAL_ 1649 Light_CustomMode 0 "Off" 1 "On" ;
VAL_ 1650 Lighting_Board_Fault 0 "OK" 1 "Addr LED Undercurrent" 2 "LED0 Undercurrent" 3 "LED1 Undercurrent" 4 "Addr LED Overcurrent" 5 "LED0 Overcurrent" 6 "LED1 Overcurrent" 7 "Light Command Watchdog" 8 "Watchdog" ;
VAL_ 1650 Light_Headlight 0 "Off" 1 "On" ;
VAL_ 1650 Light_Left_Indicator 0 "Off" 1 "On" ;
VAL_ 1650 Light_Right_Indicator 0 "Off" 1 "On" ;
VAL_ 1650 Light_BPS_Strobe 0 "Off" 1 "On" ;
VAL_ 1650 Light_Brakelight 0 "Off" 1 "On" ;
VAL_ 1650 Light_CustomMode 0 "Off" 1 "On" ;
VAL_ 1651 Lighting_Board_Fault 0 "OK" 1 "Addr LED Undercurrent" 2 "LED0 Undercurrent" 3 "LED1 Undercurrent" 4 "Addr LED Overcurrent" 5 "LED0 Overcurrent" 6 "LED1 Overcurrent" 7 "Light Command Watchdog" 8 "Watchdog" ;
VAL_ 1651 Light_Headlight 0 "Off" 1 "On" ;
VAL_ 1651 Light_Left_Indicator 0 "Off" 1 "On" ;
VAL_ 1651 Light_Right_Indicator 0 "Off" 1 "On" ;
VAL_ 1651 Light_BPS_Strobe 0 "Off" 1 "On" ;
VAL_ 1651 Light_Brakelight 0 "Off" 1 "On" ;
VAL_ 1651 Light_CustomMode 0 "Off" 1 "On" ;
VAL_ 1652 Lighting_Board_Fault 0 "OK" 1 "Addr LED Undercurrent" 2 "LED0 Undercurrent" 3 "LED1 Undercurrent" 4 "Addr LED Overcurrent" 5 "LED0 Overcurrent" 6 "LED1 Overcurrent" 7 "Light Command Watchdog" 8 "Watchdog" ;
VAL_ 1652 Light_Headlight 0 "Off" 1 "On" ;
VAL_ 1652 Light_Left_Indicator 0 "Off" 1 "On" ;
VAL_ 1652 Light_Right_Indicator 0 "Off" 1 "On" ;
VAL_ 1652 Light_BPS_Strobe 0 "Off" 1 "On" ;
VAL_ 1652 Light_Brakelight 0 "Off" 1 "On" ;
VAL_ 1652 Light_CustomMode 0 "Off" 1 "On" ;
VAL_ 1057 MC_LIMIT_OutputVoltagePWM 0 "OK" 1 "LIMIT" ;
VAL_ 1057 MC_LIMIT_MotorCurrent 0 "OK" 1 "LIMIT" ;
VAL_ 1057 MC_LIMIT_Velocity 0 "OK" 1 "LIMIT" ;
VAL_ 1057 MC_LIMIT_BusCurrent 0 "OK" 1 "LIMIT" ;
VAL_ 1057 MC_LIMIT_BusVoltageUpper 0 "OK" 1 "LIMIT" ;
VAL_ 1057 MC_LIMIT_BusVoltageLower 0 "OK" 1 "LIMIT" ;
VAL_ 1057 MC_LIMIT_MotorTemp 0 "OK" 1 "LIMIT" ;
VAL_ 1057 MC_LIMIT_Reserved 0 "OK" 1 "LIMIT" ;
VAL_ 1057 MC_FAULT_HardwareOverCurrent 0 "OK" 1 "FAULT" ;
VAL_ 1057 MC_FAULT_SoftwareOverCurrent 0 "OK" 1 "FAULT" ;
VAL_ 1057 MC_FAULT_DcBusOverVoltage 0 "OK" 1 "FAULT" ;
VAL_ 1057 MC_FAULT_BadMotorPositionHallSeq 0 "OK" 1 "FAULT" ;
VAL_ 1057 MC_FAULT_WatchdogCausedLastReset 0 "OK" 1 "FAULT" ;
VAL_ 1057 MC_FAULT_ConfigRead 0 "OK" 1 "FAULT" ;
VAL_ 1057 MC_FAULT_15vRailUnderVoltage 0 "OK" 1 "FAULT" ;
VAL_ 1057 MC_FAULT_DesaturationFault 0 "OK" 1 "FAULT" ;
VAL_ 1057 MC_FAULT_MotorOverSpeed 0 "OK" 1 "FAULT" ;
VAL_ 1057 MC_FAULT_Reserved 0 "OK" 1 "FAULT" ;
VAL_ 1953 Motor_Command_Source 0 "VCU" 1 "Tritium External" ;
SIG_VALTYPE_ 1025 MC_MotorVelocitySetpoint : 1;
SIG_VALTYPE_ 1025 MC_MotorCurrentSetpoint : 1;
SIG_VALTYPE_ 1026 MC_MotorPowerSetpoint : 1;
SIG_VALTYPE_ 1058 MC_BusVoltage : 1;
SIG_VALTYPE_ 1058 MC_BusCurrent : 1;
SIG_VALTYPE_ 1059 MC_MotorVelocity : 1;
SIG_VALTYPE_ 1059 MC_VehicleVelocity : 1;
SIG_VALTYPE_ 1060 MC_PhaseCurrentB : 1;
SIG_VALTYPE_ 1060 MC_PhaseCurrentC : 1;
SIG_VALTYPE_ 1061 MC_Vq : 1;
SIG_VALTYPE_ 1061 MC_Vd : 1;
SIG_VALTYPE_ 1062 MC_Iq : 1;
SIG_VALTYPE_ 1062 MC_Id : 1;
SIG_VALTYPE_ 1063 MC_BEMFq : 1;
SIG_VALTYPE_ 1063 MC_BEMFd : 1;
SIG_VALTYPE_ 1064 MC_Supply15V : 1;
SIG_VALTYPE_ 1065 MC_Supply1V9 : 1;
SIG_VALTYPE_ 1065 MC_Supply3V3 : 1;
SIG_VALTYPE_ 1067 MC_MotorTemp : 1;
SIG_VALTYPE_ 1067 MC_HeatsinkTemp : 1;
SIG_VALTYPE_ 1068 MC_DspBoardTemp : 1;
SIG_VALTYPE_ 1070 MC_TripOdometer : 1;
SIG_VALTYPE_ 1070 MC_DCBusAh : 1;
SIG_VALTYPE_ 1079 MC_SlipSpeed : 1;
SIG_VALTYPE_ 2046 Sine : 1;
SIG_VALTYPE_ 2046 Cosine : 1;
VAL_ 688 LWS_Fault 0 "OK" 1 "Internal Fault" ;
VAL_ 688 LWS_CalibrationStaus 0 "Sensor Not Calibrated" 1 "Sensor Calibrated" ;
VAL_ 688 LWS_Trimming_Status 0 "FAULT - Sensor Not Trimmed" 1 "Sensor Trimmed" ;
VAL_ 1984 LWS_CCW 3 "Sets the signal LWS_Angle to 0°" 5 "Resets calibration status" ;
